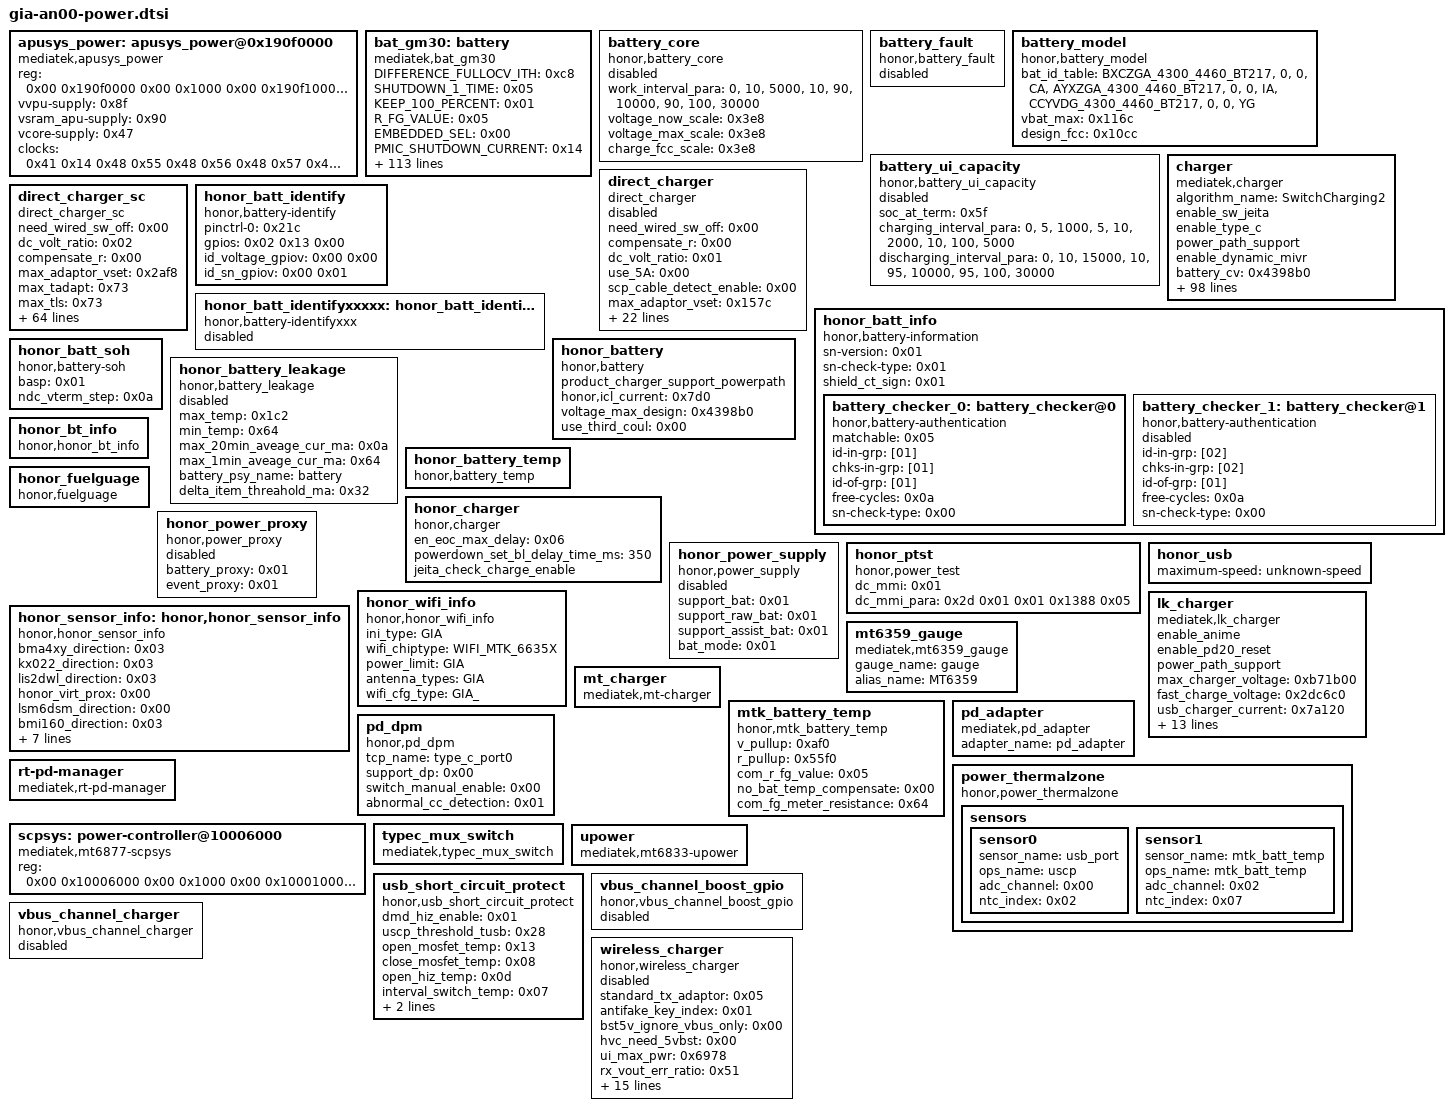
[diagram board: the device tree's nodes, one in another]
// SPDX-License-Identifier: GPL-2.0
/*
 * HONOR GIA-AN00 / MT6877V/ZA 设备树分片
 * 由实机反编译 device.dts 自动还原，节点内容保持原样
 */

/* 40 个顶层节点 */

	apusys_power: apusys_power@0x190f0000 {
			compatible = "mediatek,apusys_power";
			reg = <0x00 0x190f0000 0x00 0x1000 0x00 0x190f1000 0x00 0x1000 0x00 0x19029000 0x00 0x1000>;
			reg-names = "apusys_rpc", "apusys_pcu", "apusys_vcore";
			vvpu-supply = <0x8f>;
			vsram_apu-supply = <0x90>;
			vcore-supply = <0x47>;
			clocks = <0x41 0x14 0x48 0x55 0x48 0x56 0x48 0x57 0x48 0x58 0x48 0x59 0x48 0x03 0x48 0x16 0x48 0x1d 0x91 0x00 0x91 0x01 0x91 0x02 0x91 0x03>;
			clock-names = "mtcmos_scp_sys_vpu", "clk_top_dsp_sel", "clk_top_dsp1_sel", "clk_top_dsp2_sel", "clk_top_dsp5_sel", "clk_top_ipu_if_sel", "clk_top_mainpll_d4_d2", "clk_top_univpll_d4_d2", "clk_top_univpll_d6_d2", "clk_apupll_apupll", "clk_apupll_npupll", "clk_apupll_apupll1", "clk_apupll_apupll2";
			phandle = <0x19c>;
		};

	bat_gm30: battery {
			compatible = "mediatek,bat_gm30";
			DIFFERENCE_FULLOCV_ITH = <0xc8>;
			SHUTDOWN_1_TIME = <0x05>;
			KEEP_100_PERCENT = <0x01>;
			R_FG_VALUE = <0x05>;
			EMBEDDED_SEL = <0x00>;
			PMIC_SHUTDOWN_CURRENT = <0x14>;
			FG_METER_RESISTANCE = <0x64>;
			CAR_TUNE_VALUE = <0x1f4>;
			PMIC_MIN_VOL = <0x82dc>;
			POWERON_SYSTEM_IBOOT = <0x1f4>;
			SHUTDOWN_GAUGE0_VOLTAGE = <0x84d0>;
			TEMPERATURE_T0 = <0x32>;
			TEMPERATURE_T1 = <0x19>;
			TEMPERATURE_T2 = <0x0a>;
			TEMPERATURE_T3 = <0x00>;
			TEMPERATURE_T4 = <0xfffffff6>;
			g_FG_PSEUDO100_T0 = <0x61>;
			g_FG_PSEUDO100_T1 = <0x61>;
			g_FG_PSEUDO100_T2 = <0x61>;
			g_FG_PSEUDO100_T3 = <0x61>;
			g_FG_PSEUDO100_T4 = <0x61>;
			Q_MAX_SYS_VOLTAGE_BAT0 = <0xd16>;
			Q_MAX_SYS_VOLTAGE_BAT1 = <0xd16>;
			Q_MAX_SYS_VOLTAGE_BAT2 = <0xd16>;
			Q_MAX_SYS_VOLTAGE_BAT3 = <0xd16>;
			COM_FG_METER_RESISTANCE = <0x64>;
			COM_R_FG_VALUE = <0x00>;
			enable_tmp_intr_suspend = <0x00>;
			ACTIVE_TABLE = <0x00>;
			MULTI_TEMP_GAUGE0 = <0x01>;
			battery0_profile_t0_num = <0x64>;
			battery0_profile_t0_col = <0x04>;
			battery0_profile_t0 = <0x00 0xab72 0x15e 0x150 0x1a2 0xaaec 0x15e 0x150 0x344 0xaa7b 0x16f 0x160 0x4e7 0xaa09 0x16a 0x15c 0x689 0xa997 0x167 0x159 0x82b 0xa92a 0x177 0x168 0x9cd 0xa8bd 0x177 0x168 0xb6f 0xa848 0x177 0x168 0xd11 0xa7da 0x177 0x168 0xeb4 0xa768 0x184 0x174 0x1056 0xa6f3 0x190 0x180 0x11f8 0xa67c 0x18b 0x17b 0x139a 0xa5ff 0x178 0x169 0x139a 0xa5ff 0x178 0x169 0x153c 0xa593 0x18d 0x17d 0x16df 0xa518 0x190 0x180 0x1881 0xa4a0 0x190 0x180 0x1a23 0xa42b 0x190 0x180 0x1bc5 0xa3b5 0x190 0x180 0x1d67 0xa341 0x191 0x181 0x1f09 0xa2d4 0x1a6 0x195 0x20ac 0xa260 0x197 0x187 0x224e 0xa1f1 0x19e 0x18d 0x23f0 0xa183 0x1a9 0x198 0x2592 0xa112 0x1a3 0x192 0x2734 0xa09f 0x192 0x182 0x28d7 0xa03b 0x1a7 0x196 0x2a79 0x9fce 0x1a9 0x198 0x2c1b 0x9f68 0x1a9 0x198 0x2dbd 0x9f03 0x1a9 0x198 0x2f5f 0x9e9f 0x1a9 0x198 0x3101 0x9e3c 0x1ac 0x19b 0x32a4 0x9de0 0x1c1 0x1af 0x3446 0x9d7c 0x1c2 0x1b0 0x35e8 0x9d1e 0x1c2 0x1b0 0x378a 0x9cc6 0x1cd 0x1bb 0x392c 0x9c70 0x1e2 0x1cf 0x3acf 0x9c14 0x1f7 0x1e3 0x3c71 0x9bb8 0x20c 0x1f7 0x3e13 0x9b54 0x221 0x20b 0x3fb5 0x9ac3 0x1f6 0x1e2 0x4157 0x9a24 0x1c3 0x1b1 0x42f9 0x9998 0x1a1 0x190 0x449c 0x992f 0x190 0x180 0x463e 0x98dc 0x190 0x180 0x47e0 0x9890 0x190 0x180 0x4982 0x984b 0x190 0x180 0x4b24 0x9809 0x190 0x180 0x4cc7 0x97c6 0x188 0x178 0x4e69 0x9784 0x177 0x168 0x500b 0x974a 0x177 0x168 0x51ad 0x9718 0x18c 0x17c 0x534f 0x96df 0x190 0x180 0x54f1 0x96a9 0x190 0x180 0x5694 0x9677 0x190 0x180 0x5836 0x9645 0x190 0x180 0x59d8 0x9613 0x190 0x180 0x5b7a 0x95e9 0x190 0x180 0x5d1c 0x95b8 0x190 0x180 0x5ebf 0x9591 0x19d 0x18c 0x6061 0x956c 0x1a9 0x198 0x6203 0x9542 0x1a9 0x198 0x63a5 0x9518 0x1a9 0x198 0x6547 0x94f7 0x1a9 0x198 0x66e9 0x94d6 0x1bb 0x1a9 0x688c 0x94b4 0x1c2 0x1b0 0x6a2e 0x948b 0x1c2 0x1b0 0x6bd0 0x9453 0x1bc 0x1aa 0x6d72 0x940e 0x1a7 0x196 0x6f14 0x93b2 0x192 0x182 0x70b7 0x936c 0x190 0x180 0x7259 0x9335 0x190 0x180 0x73fb 0x92fe 0x190 0x180 0x759d 0x92c7 0x190 0x180 0x773f 0x9294 0x190 0x180 0x78e1 0x9262 0x190 0x180 0x7a84 0x9230 0x190 0x180 0x7c26 0x9204 0x190 0x180 0x7dc8 0x91da 0x19b 0x18b 0x7f6a 0x91a8 0x1a9 0x198 0x810c 0x9164 0x1a6 0x195 0x82af 0x9119 0x191 0x181 0x8451 0x90dd 0x1a4 0x193 0x85f3 0x909c 0x1a9 0x198 0x8795 0x904c 0x19e 0x18d 0x8937 0x9004 0x189 0x179 0x8ad9 0x8fe7 0x17a 0x16b 0x8c7c 0x8fde 0x18f 0x17f 0x8e1e 0x8fd6 0x1a4 0x193 0x8fc0 0x8fc7 0x1b9 0x1a7 0x9162 0x8fad 0x1da 0x1c7 0x9304 0x8f66 0x1ec 0x1d8 0x94a7 0x8eb6 0x1db 0x1c8 0x9649 0x8d46 0x1db 0x1c8 0x97eb 0x8b5b 0x204 0x1ef 0x998d 0x88ea 0x24f 0x237 0x9b2f 0x858f 0x2bb 0x29f 0x9cd1 0x802c 0x518 0x4e4 0x9e74 0x76cd 0xc4e 0xbd0 0xa016 0x6f40 0x52d 0x4f8 0xa1b8 0x6f40 0x52d 0x4f8>;
			battery0_profile_t1_num = <0x64>;
			battery0_profile_t1_col = <0x04>;
			battery0_profile_t1 = <0x00 0xaba4 0x28a 0x270 0x1a2 0xab40 0x28a 0x270 0x344 0xaadb 0x29b 0x280 0x4e7 0xaa77 0x2a3 0x288 0x689 0xaa13 0x2a3 0x288 0x82b 0xa9ac 0x2a3 0x288 0x9cd 0xa940 0x2a3 0x288 0xb6f 0xa8d3 0x28e 0x274 0xd11 0xa866 0x29b 0x280 0xeb4 0xa7f4 0x296 0x27c 0x1056 0xa783 0x293 0x279 0x11f8 0xa714 0x2a3 0x288 0x139a 0xa69f 0x2a3 0x288 0x153c 0xa62a 0x2a3 0x288 0x16df 0xa5ae 0x291 0x277 0x1881 0xa536 0x28a 0x270 0x1a23 0xa4c1 0x294 0x27a 0x1bc5 0xa44b 0x29e 0x283 0x1d67 0xa3d7 0x28b 0x271 0x1f09 0xa368 0x2a1 0x286 0x20ac 0xa2f3 0x2a3 0x288 0x224e 0xa27e 0x2a3 0x288 0x23f0 0xa20d 0x2a3 0x288 0x2592 0xa1a1 0x2a9 0x28e 0x2734 0xa134 0x2bc 0x2a0 0x28d7 0xa0c7 0x2bc 0x2a0 0x2a79 0xa05a 0x2bc 0x2a0 0x2c1b 0x9fee 0x2bc 0x2a0 0x2dbd 0x9f85 0x2c7 0x2ab 0x2f5f 0x9f21 0x2d5 0x2b8 0x3101 0x9ebd 0x2d8 0x2bb 0x32a4 0x9e58 0x2ed 0x2cf 0x3446 0x9dfc 0x302 0x2e3 0x35e8 0x9d9a 0x307 0x2e8 0x378a 0x9d3a 0x312 0x2f3 0x392c 0x9cde 0x32f 0x30e 0x3acf 0x9c82 0x355 0x333 0x3c71 0x9c26 0x36a 0x347 0x3e13 0x9bca 0x393 0x36e 0x3fb5 0x9b54 0x38d 0x369 0x4157 0x9abf 0x349 0x327 0x42f9 0x9a21 0x2e8 0x2ca 0x449c 0x9999 0x29f 0x284 0x463e 0x992c 0x28a 0x270 0x47e0 0x98d8 0x275 0x25c 0x4982 0x988b 0x271 0x258 0x4b24 0x9840 0x265 0x24c 0x4cc7 0x97fb 0x260 0x248 0x4e69 0x97c0 0x275 0x25c 0x500b 0x9786 0x28a 0x270 0x51ad 0x974b 0x28a 0x270 0x534f 0x9711 0x279 0x260 0x54f1 0x96db 0x27e 0x264 0x5694 0x96a6 0x281 0x267 0x5836 0x966f 0x276 0x25d 0x59d8 0x9645 0x28a 0x270 0x5b7a 0x9613 0x28a 0x270 0x5d1c 0x95e7 0x28a 0x270 0x5ebf 0x95be 0x28a 0x270 0x6061 0x9594 0x28a 0x270 0x6203 0x956a 0x28a 0x270 0x63a5 0x9540 0x28b 0x271 0x6547 0x951e 0x2a0 0x285 0x66e9 0x94fd 0x2a3 0x288 0x688c 0x94db 0x2b1 0x295 0x6a2e 0x94ba 0x2bc 0x2a0 0x6bd0 0x9496 0x2bc 0x2a0 0x6d72 0x946c 0x2bc 0x2a0 0x6f14 0x9442 0x2bc 0x2a0 0x70b7 0x9411 0x2a9 0x28e 0x7259 0x93df 0x294 0x27a 0x73fb 0x93ad 0x28a 0x270 0x759d 0x937b 0x284 0x26a 0x773f 0x9347 0x271 0x258 0x78e1 0x930d 0x271 0x258 0x7a84 0x92e2 0x284 0x26a 0x7c26 0x92b2 0x27b 0x262 0x7dc8 0x9288 0x271 0x258 0x7f6a 0x9261 0x271 0x258 0x810c 0x922d 0x271 0x258 0x82af 0x91ea 0x271 0x258 0x8451 0x91a7 0x271 0x258 0x85f3 0x916a 0x271 0x258 0x8795 0x912b 0x271 0x258 0x8937 0x90e3 0x271 0x258 0x8ad9 0x9095 0x271 0x258 0x8c7c 0x906c 0x271 0x258 0x8e1e 0x9062 0x285 0x26b 0x8fc0 0x9053 0x27a 0x261 0x9162 0x9047 0x289 0x26f 0x9304 0x9035 0x2a3 0x288 0x94a7 0x900b 0x2aa 0x28f 0x9649 0x8fb7 0x2d4 0x2b7 0x97eb 0x8e75 0x2c0 0x2a4 0x998d 0x8cb2 0x2dd 0x2c0 0x9b2f 0x8a60 0x313 0x2f4 0x9cd1 0x8746 0x37b 0x357 0x9e74 0x829b 0x508 0x4d4 0xa016 0x7aaa 0xa3c 0x9d3 0xa1b8 0x7166 0xa0f 0x9a8>;
			battery0_profile_t2_num = <0x64>;
			battery0_profile_t2_col = <0x04>;
			battery0_profile_t2 = <0x00 0xabcc 0x2bc 0x2a0 0x1a2 0xab81 0x2bc 0x2a0 0x344 0xab21 0x43f 0x414 0x4e7 0xaabd 0x4fb 0x4c8 0x689 0xaa59 0x4fb 0x4c8 0x82b 0xa9f2 0x4f6 0x4c3 0x9cd 0xa986 0x4e2 0x4b0 0xb6f 0xa921 0x4f7 0x4c4 0xd11 0xa8af 0x4ea 0x4b8 0xeb4 0xa83f 0x4e2 0x4b0 0x1056 0xa7cf 0x4e2 0x4b0 0x11f8 0xa75a 0x4e2 0x4b0 0x139a 0xa6e5 0x4e2 0x4b0 0x153c 0xa670 0x4e2 0x4b0 0x16df 0xa5fb 0x4e2 0x4b0 0x1881 0xa580 0x4d4 0x4a3 0x1a23 0xa50a 0x4d3 0x4a2 0x1bc5 0xa499 0x4dd 0x4ab 0x1d67 0xa41c 0x4c9 0x498 0x1f09 0xa3a5 0x4c9 0x498 0x20ac 0xa337 0x4dc 0x4aa 0x224e 0xa2c4 0x4d3 0x4a2 0x23f0 0xa24f 0x4c9 0x498 0x2592 0xa1dd 0x4cf 0x49e 0x2734 0xa170 0x4e2 0x4b0 0x28d7 0xa103 0x4e2 0x4b0 0x2a79 0xa096 0x4f5 0x4c2 0x2c1b 0xa02a 0x4fb 0x4c8 0x2dbd 0x9fc1 0x506 0x4d3 0x2f5f 0x9f5d 0x51b 0x4e7 0x3101 0x9ef9 0x530 0x4fb 0x32a4 0x9e94 0x545 0x50f 0x3446 0x9e30 0x55a 0x523 0x35e8 0x9dcc 0x56f 0x537 0x378a 0x9d67 0x583 0x54b 0x392c 0x9d06 0x5a0 0x566 0x3acf 0x9ca9 0x5c3 0x588 0x3c71 0x9c44 0x5c3 0x588 0x3e13 0x9bd8 0x5c3 0x588 0x3fb5 0x9b5e 0x5a3 0x569 0x4157 0x9ad7 0x556 0x51f 0x42f9 0x9a4c 0x4fd 0x4ca 0x449c 0x99c9 0x4be 0x48d 0x463e 0x9954 0x47f 0x451 0x47e0 0x98f8 0x47e 0x450 0x4982 0x98a1 0x46d 0x440 0x4b24 0x9852 0x465 0x438 0x4cc7 0x980a 0x465 0x438 0x4e69 0x97c7 0x465 0x438 0x500b 0x9784 0x465 0x438 0x51ad 0x974a 0x465 0x438 0x534f 0x970f 0x465 0x438 0x54f1 0x96d5 0x458 0x42c 0x5694 0x969e 0x455 0x429 0x5836 0x966c 0x465 0x438 0x59d8 0x963a 0x465 0x438 0x5b7a 0x9607 0x465 0x438 0x5d1c 0x95d5 0x465 0x438 0x5ebf 0x95a9 0x465 0x438 0x6061 0x957f 0x46f 0x442 0x6203 0x9555 0x47e 0x450 0x63a5 0x952c 0x47f 0x451 0x6547 0x950a 0x494 0x465 0x66e9 0x94e9 0x4a9 0x479 0x688c 0x94c2 0x4a2 0x473 0x6a2e 0x949c 0x4a1 0x472 0x6bd0 0x947a 0x4b0 0x480 0x6d72 0x9459 0x4b0 0x480 0x6f14 0x9437 0x4b0 0x480 0x70b7 0x941e 0x4c3 0x492 0x7259 0x93f9 0x4ba 0x48a 0x73fb 0x93d3 0x4b0 0x480 0x759d 0x93ad 0x4aa 0x47a 0x773f 0x937a 0x495 0x466 0x78e1 0x9348 0x480 0x452 0x7a84 0x9316 0x47e 0x450 0x7c26 0x92ea 0x47e 0x450 0x7dc8 0x92c0 0x489 0x45b 0x7f6a 0x9296 0x497 0x468 0x810c 0x926a 0x497 0x468 0x82af 0x922e 0x497 0x468 0x8451 0x91ec 0x4ab 0x47b 0x85f3 0x91af 0x4b0 0x480 0x8795 0x9170 0x4b0 0x480 0x8937 0x9127 0x4b0 0x480 0x8ad9 0x90d6 0x4b8 0x488 0x8c7c 0x9093 0x4e1 0x4af 0x8e1e 0x9079 0x4e2 0x4b0 0x8fc0 0x9067 0x503 0x4d0 0x9162 0x9051 0x514 0x4e0 0x9304 0x903b 0x52d 0x4f8 0x94a7 0x9024 0x567 0x530 0x9649 0x8ff1 0x591 0x558 0x97eb 0x8f41 0x5d0 0x594 0x998d 0x8dbf 0x60f 0x5d1 0x9b2f 0x8bb0 0x681 0x63e 0x9cd1 0x88f6 0x737 0x6ed 0x9e74 0x8518 0x892 0x83a 0xa016 0x7f24 0xbdf 0xb65 0xa1b8 0x7242 0xc80 0xc00>;
			battery0_profile_t3_num = <0x64>;
			battery0_profile_t3_col = <0x04>;
			battery0_profile_t3 = <0x00 0xab9a 0x7bc 0x76d 0x1a2 0xab36 0x7b8 0x769 0x344 0xaad1 0x8d5 0x87b 0x4e7 0xaa68 0x960 0x900 0x689 0xa9ff 0x960 0x900 0x82b 0xa998 0x960 0x900 0x9cd 0xa92c 0x960 0x900 0xb6f 0xa8bf 0x94b 0x8ec 0xd11 0xa852 0x947 0x8e8 0xeb4 0xa7df 0x93a 0x8dc 0x1056 0xa768 0x91b 0x8be 0x11f8 0xa6f3 0x8fc 0x8a0 0x139a 0xa67e 0x8fb 0x89f 0x153c 0xa609 0x8e6 0x88b 0x16df 0xa594 0x8d1 0x877 0x1881 0xa51f 0x8bc 0x863 0x1a23 0xa4aa 0x8b1 0x858 0x1bc5 0xa435 0x8ab 0x852 0x1d67 0xa3c0 0x896 0x83e 0x1f09 0xa34a 0x881 0x82a 0x20ac 0xa2d5 0x87f 0x828 0x224e 0xa266 0x87f 0x828 0x23f0 0xa1f5 0x875 0x81e 0x2592 0xa183 0x866 0x810 0x2734 0xa116 0x868 0x812 0x28d7 0xa0a9 0x87d 0x826 0x2a79 0xa03c 0x892 0x83a 0x2c1b 0x9fd6 0x898 0x840 0x2dbd 0x9f6d 0x898 0x840 0x2f5f 0x9f03 0x89f 0x847 0x3101 0x9e9f 0x8b7 0x85e 0x32a4 0x9e3a 0x8e0 0x885 0x3446 0x9dd6 0x8e3 0x888 0x35e8 0x9d72 0x8f3 0x897 0x378a 0x9d09 0x8fc 0x8a0 0x392c 0x9c9f 0x8fc 0x8a0 0x3acf 0x9c38 0x8f9 0x89d 0x3c71 0x9bc3 0x8e4 0x889 0x3e13 0x9b46 0x8bb 0x862 0x3fb5 0x9ac2 0x871 0x81b 0x4157 0x9a3c 0x81e 0x7cb 0x42f9 0x99c0 0x7d9 0x789 0x449c 0x9954 0x7b3 0x764 0x463e 0x98f0 0x79e 0x750 0x47e0 0x9894 0x78a 0x73d 0x4982 0x9845 0x785 0x738 0x4b24 0x97fa 0x779 0x72c 0x4cc7 0x97b2 0x76c 0x720 0x4e69 0x9770 0x770 0x724 0x500b 0x9736 0x785 0x738 0x51ad 0x96fb 0x79a 0x74c 0x534f 0x96c1 0x78d 0x740 0x54f1 0x9686 0x785 0x738 0x5694 0x964e 0x78e 0x741 0x5836 0x961c 0x7a3 0x755 0x59d8 0x95ea 0x7b8 0x769 0x5b7a 0x95c0 0x7cd 0x77d 0x5d1c 0x958f 0x7d0 0x780 0x5ebf 0x9563 0x7de 0x78d 0x6061 0x9539 0x7e9 0x798 0x6203 0x9511 0x7f4 0x7a3 0x63a5 0x94f0 0x81e 0x7cb 0x6547 0x94ce 0x848 0x7f3 0x66e9 0x94a5 0x83b 0x7e7 0x688c 0x9481 0x842 0x7ed 0x6a2e 0x9460 0x861 0x80b 0x6bd0 0x943e 0x87f 0x828 0x6d72 0x941e 0x881 0x82a 0x6f14 0x9405 0x896 0x83e 0x70b7 0x93ec 0x8bd 0x864 0x7259 0x93d2 0x8ca 0x870 0x73fb 0x93b5 0x8ca 0x870 0x759d 0x9391 0x8d0 0x876 0x773f 0x9367 0x8e3 0x888 0x78e1 0x933d 0x8e3 0x888 0x7a84 0x9314 0x8f6 0x89a 0x7c26 0x92e4 0x8fc 0x8a0 0x7dc8 0x92b6 0x912 0x8b5 0x7f6a 0x9289 0x943 0x8e4 0x810c 0x9255 0x97f 0x91e 0x82af 0x9211 0x9a9 0x946 0x8451 0x91ce 0x9d3 0x96e 0x85f3 0x918b 0xa0d 0x9a6 0x8795 0x9143 0xa4c 0x9e3 0x8937 0x90ee 0xa92 0xa26 0x8ad9 0x9094 0xae6 0xa76 0x8c7c 0x906b 0xb3a 0xac7 0x8e1e 0x9049 0xbb7 0xb3f 0x8fc0 0x902e 0xc45 0xbc7 0x9162 0x9015 0xcfc 0xc77 0x9304 0x8ff5 0xde6 0xd58 0x94a7 0x8fbe 0xf07 0xe6d 0x9649 0x8f50 0x106b 0xfc3 0x97eb 0x8e01 0x1222 0x1168 0x998d 0x8c09 0x1494 0x13c1 0x9b2f 0x895f 0x18a6 0x17aa 0x9cd1 0x8584 0x20a5 0x1f57 0x9e74 0x7fd2 0x29d9 0x282c 0xa016 0x7684 0x16f3 0x1608 0xa1b8 0x7684 0x16f3 0x1608>;
			battery0_profile_t4_num = <0x64>;
			battery0_profile_t4_col = <0x04>;
			battery0_profile_t4 = <0x00 0xabc2 0x128e 0x11d0 0x1a2 0xab34 0x128e 0x11d0 0x344 0xaab3 0x129f 0x11e0 0x4e7 0xaa40 0x12b4 0x11f4 0x689 0xa9d3 0x12a6 0x11e7 0x82b 0xa965 0x1275 0x11b8 0x9cd 0xa8f0 0x1274 0x11b7 0xb6f 0xa883 0x124a 0x118f 0xd11 0xa80f 0x1220 0x1166 0xeb4 0xa799 0x11f6 0x113e 0x1056 0xa722 0x11cc 0x1116 0x11f8 0xa6ad 0x11a2 0x10ed 0x139a 0xa638 0x117a 0x10c7 0x153c 0xa5c3 0x1165 0x10b3 0x16df 0xa54e 0x1150 0x109f 0x1881 0xa4d9 0x113b 0x108b 0x1a23 0xa464 0x1130 0x1080 0x1bc5 0xa3f1 0x1130 0x1080 0x1d67 0xa384 0x112e 0x107e 0x1f09 0xa30e 0x1119 0x106a 0x20ac 0xa299 0x1104 0x1056 0x224e 0xa22a 0x10fe 0x1050 0x23f0 0xa1b9 0x10f4 0x1046 0x2592 0xa147 0x10eb 0x103e 0x2734 0xa0da 0x10fc 0x104e 0x28d7 0xa06d 0x10e7 0x103a 0x2a79 0xa000 0x10f8 0x104a 0x2c1b 0x9f94 0x10fe 0x1050 0x2dbd 0x9f27 0x10fe 0x1050 0x2f5f 0x9eba 0x10fe 0x1050 0x3101 0x9e4f 0x1101 0x1053 0x32a4 0x9dea 0x1116 0x1067 0x3446 0x9d7e 0x1117 0x1068 0x35e8 0x9d0b 0x1108 0x105a 0x378a 0x9c96 0x10e7 0x103a 0x392c 0x9c21 0x10bd 0x1012 0x3acf 0x9bab 0x1090 0xfe6 0x3c71 0x9b2d 0x1052 0xfab 0x3e13 0x9ab0 0x1027 0xf82 0x3fb5 0x9a37 0xffc 0xf58 0x4157 0x99c6 0xfd2 0xf30 0x42f9 0x995c 0xfb1 0xf10 0x449c 0x98fa 0xf9c 0xefc 0x463e 0x989e 0xf87 0xee8 0x47e0 0x984a 0xf72 0xed4 0x4982 0x97fd 0xf7f 0xee0 0x4b24 0x97b2 0xf7a 0xedc 0x4cc7 0x976a 0xf6e 0xed0 0x4e69 0x9729 0xf73 0xed5 0x500b 0x96ee 0xf87 0xee8 0x51ad 0x96b4 0xf87 0xee8 0x534f 0x9679 0xf98 0xef8 0x54f1 0x9644 0xfad 0xf0c 0x5694 0x9612 0xfb9 0xf18 0x5836 0x95de 0xfb9 0xf18 0x59d8 0x95a4 0xfbb 0xf1a 0x5b7a 0x957a 0xfe5 0xf42 0x5d1c 0x9550 0xffd 0xf59 0x5ebf 0x9527 0x1012 0xf6d 0x6061 0x94fd 0x1027 0xf82 0x6203 0x94d5 0x1041 0xf9b 0x63a5 0x94b3 0x1069 0xfc1 0x6547 0x9489 0x107e 0xfd5 0x66e9 0x946e 0x10a6 0xffc 0x688c 0x944f 0x10c1 0x1015 0x6a2e 0x9432 0x10e0 0x1033 0x6bd0 0x9419 0x1104 0x1056 0x6d72 0x9400 0x111f 0x1070 0x6f14 0x93f0 0x1172 0x10bf 0x70b7 0x93d8 0x11b3 0x10fe 0x7259 0x93be 0x11e3 0x112c 0x73fb 0x93a5 0x1218 0x115f 0x759d 0x938a 0x1256 0x119a 0x773f 0x9367 0x1293 0x11d5 0x78e1 0x933d 0x12bd 0x11fd 0x7a84 0x931b 0x130d 0x124a 0x7c26 0x92ee 0x1360 0x129a 0x7dc8 0x92bc 0x13bf 0x12f5 0x7f6a 0x9287 0x1428 0x135a 0x810c 0x924a 0x1490 0x13bd 0x82af 0x91ff 0x14f9 0x1422 0x8451 0x91bb 0x1588 0x14ac 0x85f3 0x9177 0x163d 0x1559 0x8795 0x912a 0x16fb 0x1610 0x8937 0x90d3 0x17bf 0x16cc 0x8ad9 0x907d 0x1897 0x179b 0x8c7c 0x9043 0x1992 0x188c 0x8e1e 0x9021 0x1acb 0x19b9 0x8fc0 0x9000 0x1c47 0x1b25 0x9162 0x8fde 0x1e12 0x1cde 0x9304 0x8fb6 0x204a 0x1eff 0x94a7 0x8f78 0x231a 0x21b3 0x9649 0x8f0a 0x26b5 0x2529 0x97eb 0x8dc4 0x2bef 0x2a2d 0x998d 0x8bd4 0x35ff 0x33d6 0x9b2f 0x8967 0x4376 0x40c3 0x9cd1 0x85fa 0x3dd1 0x3b58 0x9e74 0x835e 0x3746 0x3510 0xa016 0x835e 0x3746 0x3510 0xa1b8 0x835e 0x3746 0x3510>;
			g_PMIC_MIN_VOL_row = <0x04>;
			g_PMIC_MIN_VOL_col = <0x0a>;
			g_PMIC_MIN_VOL = <0x82dc 0x82dc 0x82dc 0x82dc 0x80e8 0x80e8 0x80e8 0x80e8 0x82dc 0x82dc 0x82dc 0x82dc 0x7dc8 0x7dc8 0x7dc8 0x7dc8 0x7918 0x7918 0x7918 0x7918 0x7b0c 0x7b0c 0x7b0c 0x7b0c 0x7918 0x7918 0x7918 0x7918 0x7918 0x7918 0x7918 0x7918 0x7918 0x7918 0x7918 0x7918 0x7918 0x7918 0x7918 0x79e0>;
			g_PON_SYS_IBOOT_row = <0x04>;
			g_PON_SYS_IBOOT_col = <0x0a>;
			g_PON_SYS_IBOOT = <0x1388 0x1388 0x1388 0x1388 0x1388 0x1388 0x1388 0x1388 0x1388 0x1388 0x1388 0x1388 0x1388 0x1388 0x1388 0x1388 0x1388 0x1388 0x1388 0x1388 0x1388 0x1388 0x1388 0x1388 0x1388 0x1388 0x1388 0x1388 0x1388 0x1388 0x1388 0x1388 0x1388 0x1388 0x1388 0x1388 0x1388 0x1388 0x1388 0x1388>;
			g_QMAX_SYS_VOL_row = <0x04>;
			g_QMAX_SYS_VOL_col = <0x0a>;
			g_QMAX_SYS_VOL = <0x8886 0x8886 0x8886 0x8886 0x8886 0x8886 0x8886 0x8886 0x85ca 0x85ca 0x85ca 0x85ca 0x85ca 0x85ca 0x85ca 0x85ca 0x85ca 0x85ca 0x85ca 0x85ca 0x7ef4 0x7ef4 0x7ef4 0x7ef4 0x8020 0x8020 0x8020 0x8020 0x8020 0x8020 0x8020 0x8020 0x8020 0x8020 0x8020 0x8020 0x8020 0x8020 0x8020 0x8020>;
			g_FG_PSEUDO100_row = <0x04>;
			g_FG_PSEUDO100_col = <0x0a>;
			g_FG_PSEUDO100 = <0x64 0x64 0x64 0x64 0x64 0x64 0x64 0x64 0x64 0x64 0x64 0x64 0x64 0x64 0x64 0x64 0x64 0x64 0x64 0x64 0x64 0x64 0x64 0x64 0x64 0x64 0x64 0x64 0x64 0x64 0x64 0x64 0x64 0x64 0x64 0x64 0x64 0x64 0x64 0x64>;
			phandle = <0x141>;
			bat_para = "BXC_ZGA", "250000", "350000", "AYX_ZGA", "830000", "960000", "CCY_VDG", "0", "0";
			ntc_compensation_is = <0x01>;
			ntc_temp_compensation_para = "11000", "150", "10000", "130", "9000", "100", "8000", "80", "7000", "60", "6000", "50", "5000", "40", "3000", "30", "2000", "20";
			min_fcc = <0x2b4df0>;
			max_fcc = <0x419ce0>;
			dlpt_optimization;
			soc_algo_factor = <0x0f>;
			MULTI_BATTERY = <0x00>;
			SLEEP_CURRENT_AVG = <0x1f4>;
			low_capacity_volt_check_en = <0x00>;
			battery1_profile_t0_num = <0x64>;
			battery1_profile_t0_col = <0x04>;
			battery1_profile_t0 = <0x00 0xab90 0x15e 0x150 0x1a6 0xab11 0x15e 0x150 0x34b 0xaaa1 0x16f 0x160 0x4f1 0xaa33 0x177 0x168 0x697 0xa9c5 0x177 0x168 0x83d 0xa958 0x177 0x168 0x9e2 0xa8ea 0x177 0x168 0xb88 0xa87c 0x177 0x168 0xd2e 0xa807 0x177 0x168 0xed3 0xa797 0x186 0x176 0x1079 0xa725 0x190 0x180 0x121f 0xa6af 0x190 0x180 0x13c5 0xa639 0x190 0x180 0x156a 0xa5c3 0x190 0x180 0x1710 0xa54d 0x190 0x180 0x18b6 0xa4d0 0x190 0x180 0x1a5b 0xa45c 0x190 0x180 0x1c01 0xa3eb 0x190 0x180 0x1da7 0xa375 0x190 0x180 0x1f4d 0xa2fe 0x190 0x180 0x20f2 0xa288 0x190 0x180 0x2298 0xa219 0x190 0x180 0x243e 0xa1aa 0x19e 0x18d 0x25e3 0xa137 0x19f 0x18e 0x2789 0xa0c7 0x197 0x187 0x292f 0xa060 0x1a9 0x198 0x2ad5 0x9ff3 0x1a9 0x198 0x2c7a 0x9f8d 0x1a9 0x198 0x2e20 0x9f28 0x1b9 0x1a7 0x2fc6 0x9ec2 0x1c2 0x1b0 0x316c 0x9e5d 0x1c2 0x1b0 0x3311 0x9dfa 0x1c2 0x1b0 0x34b7 0x9d9d 0x1c2 0x1b0 0x365d 0x9d40 0x1d7 0x1c4 0x3802 0x9ce3 0x1db 0x1c8 0x39a8 0x9c87 0x1e9 0x1d5 0x3b4e 0x9c2a 0x1fe 0x1ea 0x3cf4 0x9bc8 0x213 0x1fe 0x3e99 0x9b55 0x21f 0x209 0x403f 0x9aa4 0x1cb 0x1b9 0x41e5 0x9a0a 0x19c 0x18c 0x438a 0x9996 0x190 0x180 0x4530 0x993a 0x185 0x175 0x46d6 0x98e8 0x177 0x168 0x487c 0x989e 0x17a 0x16b 0x4a21 0x985a 0x18f 0x17f 0x4bc7 0x9817 0x190 0x180 0x4d6d 0x97d3 0x17f 0x170 0x4f12 0x9795 0x184 0x174 0x50b8 0x975a 0x190 0x180 0x525e 0x9720 0x190 0x180 0x5404 0x96ee 0x190 0x180 0x55a9 0x96bb 0x190 0x180 0x574f 0x9681 0x190 0x180 0x58f5 0x9652 0x19e 0x18d 0x5a9a 0x9623 0x19f 0x18e 0x5c40 0x95f3 0x196 0x186 0x5de6 0x95c8 0x1a4 0x193 0x5f8c 0x9596 0x17a 0x16b 0x6131 0x9573 0x19e 0x18d 0x62d7 0x954b 0x1a9 0x198 0x647d 0x9521 0x19d 0x18c 0x6622 0x94f9 0x198 0x188 0x67c8 0x94d8 0x1ad 0x19c 0x696e 0x94b6 0x1c2 0x1b0 0x6b14 0x9494 0x1d8 0x1c5 0x6cb9 0x945d 0x1c9 0x1b7 0x6e5f 0x940b 0x1a6 0x195 0x7005 0x93b3 0x186 0x176 0x71aa 0x9368 0x17d 0x16e 0x7350 0x9335 0x190 0x180 0x74f6 0x9303 0x190 0x180 0x769c 0x92d0 0x190 0x180 0x7841 0x929d 0x19f 0x18e 0x79e7 0x926b 0x1a9 0x198 0x7b8d 0x923b 0x1a9 0x198 0x7d33 0x9210 0x1a5 0x194 0x7ed8 0x91dd 0x190 0x180 0x807e 0x91aa 0x190 0x180 0x8224 0x916a 0x190 0x180 0x83c9 0x9127 0x190 0x180 0x856f 0x90e7 0x199 0x189 0x8715 0x90a8 0x1a9 0x198 0x88bb 0x905c 0x1a8 0x197 0x8a60 0x9010 0x193 0x183 0x8c06 0x8ff7 0x190 0x180 0x8dac 0x8fe6 0x182 0x173 0x8f51 0x8fda 0x18c 0x17c 0x90f7 0x8fcf 0x1b0 0x19f 0x929d 0x8fbb 0x1c7 0x1b5 0x9443 0x8f91 0x1f1 0x1dd 0x95e8 0x8ee8 0x1cc 0x1ba 0x978e 0x8d9e 0x1c2 0x1b0 0x9934 0x8bdf 0x1e6 0x1d3 0x9ad9 0x89a7 0x21d 0x207 0x9c7f 0x86b5 0x254 0x23c 0x9e25 0x829b 0x2cb 0x2ae 0x9fcb 0x7a12 0x7fc 0x7aa 0xa170 0x6f36 0x4fb 0x4c8 0xa316 0x6f36 0x4fb 0x4c8>;
			battery1_profile_t1_num = <0x64>;
			battery1_profile_t1_col = <0x04>;
			battery1_profile_t1 = <0x1a6 0xab51 0x28a 0x270 0x34b 0xaaee 0x28a 0x270 0x4f1 0xaa88 0x28a 0x270 0x697 0xaa23 0x28a 0x270 0x83d 0xa9be 0x28a 0x270 0x9e2 0xa958 0x28c 0x272 0xb88 0xa8ea 0x2a1 0x286 0xd2e 0xa875 0x290 0x276 0xed3 0xa805 0x28a 0x270 0x1079 0xa793 0x28a 0x270 0x121f 0xa71d 0x28a 0x270 0x13c5 0xa6a7 0x28a 0x270 0x156a 0xa631 0x28a 0x270 0x1710 0xa5bb 0x28a 0x270 0x18b6 0xa545 0x28a 0x270 0x1a5b 0xa4cf 0x28a 0x270 0x1c01 0xa459 0x28a 0x270 0x1da7 0xa3e3 0x28a 0x270 0x1f4d 0xa36c 0x28a 0x270 0x20f2 0xa2f6 0x28a 0x270 0x2298 0xa287 0x29c 0x281 0x243e 0xa213 0x295 0x27b 0x25e3 0xa1a0 0x28a 0x270 0x2789 0xa132 0x291 0x277 0x292f 0xa0c5 0x2a6 0x28b 0x2ad5 0xa060 0x2bb 0x29f 0x2c7a 0x9ff3 0x2bc 0x2a0 0x2e20 0x9f8c 0x2cc 0x2af 0x2fc6 0x9f22 0x2c9 0x2ac 0x316c 0x9eba 0x2cc 0x2af 0x3311 0x9e5c 0x2ee 0x2d0 0x34b7 0x9df7 0x2ee 0x2d0 0x365d 0x9d9a 0x303 0x2e4 0x3802 0x9d3d 0x318 0x2f8 0x39a8 0x9cdb 0x32e 0x30d 0x3b4e 0x9c7a 0x343 0x322 0x3cf4 0x9c18 0x358 0x336 0x3e99 0x9ba9 0x367 0x344 0x403f 0x9b22 0x33d 0x31c 0x41e5 0x9a7d 0x2da 0x2bd 0x438a 0x99ec 0x28f 0x275 0x4530 0x9977 0x266 0x24d 0x46d6 0x9917 0x258 0x240 0x487c 0x98c6 0x25b 0x243 0x4a21 0x9882 0x270 0x257 0x4bc7 0x9836 0x25d 0x245 0x4d6d 0x97f1 0x258 0x240 0x4f12 0x97b3 0x258 0x240 0x50b8 0x9778 0x258 0x240 0x525e 0x973d 0x258 0x240 0x5404 0x9702 0x258 0x240 0x55a9 0x96cf 0x258 0x240 0x574f 0x969d 0x26a 0x251 0x58f5 0x966a 0x263 0x24b 0x5a9a 0x963c 0x262 0x24a 0x5c40 0x960f 0x26b 0x252 0x5de6 0x95dd 0x25a 0x242 0x5f8c 0x95b3 0x26f 0x256 0x6131 0x9589 0x271 0x258 0x62d7 0x9565 0x281 0x267 0x647d 0x953f 0x28a 0x270 0x6622 0x9517 0x28a 0x270 0x67c8 0x94f6 0x28a 0x270 0x696e 0x94d4 0x28a 0x270 0x6b14 0x94b2 0x2a0 0x285 0x6cb9 0x9490 0x2b5 0x299 0x6e5f 0x9468 0x2ae 0x293 0x7005 0x943a 0x299 0x27e 0x71aa 0x9405 0x27e 0x264 0x7350 0x93cc 0x258 0x240 0x74f6 0x93a2 0x258 0x240 0x769c 0x9370 0x258 0x240 0x7841 0x933d 0x267 0x24e 0x79e7 0x930b 0x266 0x24d 0x7b8d 0x92d8 0x251 0x239 0x7d33 0x92a8 0x243 0x22c 0x7ed8 0x9287 0x258 0x240 0x807e 0x925d 0x258 0x240 0x8224 0x9225 0x258 0x240 0x83c9 0x91ea 0x265 0x24c 0x856f 0x91ab 0x268 0x24f 0x8715 0x916c 0x25d 0x245 0x88bb 0x9138 0x271 0x258 0x8a60 0x90ec 0x271 0x258 0x8c06 0x9099 0x24c 0x234 0x8dac 0x9072 0x24d 0x235 0x8f51 0x9066 0x262 0x24a 0x90f7 0x905b 0x271 0x258 0x929d 0x904a 0x274 0x25b 0x9443 0x9039 0x289 0x26f 0x95e8 0x9018 0x29e 0x283 0x978e 0x8fa4 0x2a3 0x288 0x9934 0x8e8e 0x2af 0x294 0x9ad9 0x8cdc 0x2cc 0x2af 0x9c7f 0x8aac 0x2fa 0x2dc 0x9e25 0x87e4 0x33b 0x31a 0x9fcb 0x83ac 0x3f9 0x3d0 0xa170 0x7af7 0xb3e 0xacb 0xa316 0x6fd6 0x672 0x630>;
			battery1_profile_t2_num = <0x64>;
			battery1_profile_t2_col = <0x04>;
			battery1_profile_t2 = <0x00 0xabe0 0x2bc 0x2a0 0x1a6 0xab94 0x2bc 0x2a0 0x34b 0xab34 0x402 0x3d9 0x4f1 0xaace 0x497 0x468 0x697 0xaa69 0x497 0x468 0x83d 0xaa04 0x497 0x468 0x9e2 0xa99e 0x497 0x468 0xb88 0xa930 0x497 0x468 0xd2e 0xa8c3 0x497 0x468 0xed3 0xa855 0x497 0x468 0x1079 0xa7e3 0x48c 0x45d 0x121f 0xa76d 0x47e 0x450 0x13c5 0xa6f7 0x47e 0x450 0x156a 0xa681 0x47e 0x450 0x1710 0xa60b 0x47e 0x450 0x18b6 0xa595 0x47e 0x450 0x1a5b 0xa51f 0x47e 0x450 0x1c01 0xa4a9 0x47e 0x450 0x1da7 0xa433 0x47e 0x450 0x1f4d 0xa3bc 0x47e 0x450 0x20f2 0xa346 0x47e 0x450 0x2298 0xa2d0 0x46c 0x43f 0x243e 0xa25e 0x473 0x445 0x25e3 0xa1f0 0x488 0x45a 0x2789 0xa17f 0x497 0x468 0x292f 0xa10a 0x497 0x468 0x2ad5 0xa09d 0x497 0x468 0x2c7a 0xa037 0x4ab 0x47b 0x2e20 0x9fcb 0x4b0 0x480 0x2fc6 0x9f62 0x4c8 0x497 0x316c 0x9efa 0x4e2 0x4b0 0x3311 0x9e90 0x4e6 0x4b4 0x34b7 0x9e33 0x4fb 0x4c8 0x365d 0x9dce 0x510 0x4dc 0x3802 0x9d68 0x525 0x4f0 0x39a8 0x9d03 0x53b 0x505 0x3b4e 0x9c9e 0x550 0x51a 0x3cf4 0x9c34 0x55f 0x528 0x3e99 0x9bbc 0x558 0x521 0x403f 0x9b2d 0x504 0x4d1 0x41e5 0x9a96 0x49c 0x46d 0x438a 0x9a10 0x460 0x433 0x4530 0x999a 0x436 0x40b 0x46d6 0x9935 0x41a 0x3f0 0x487c 0x98e1 0x417 0x3ed 0x4a21 0x988d 0x402 0x3d9 0x4bc7 0x9849 0x401 0x3d8 0x4d6d 0x9805 0x401 0x3d8 0x4f12 0x97c2 0x401 0x3d8 0x50b8 0x9782 0x401 0x3d8 0x525e 0x9747 0x401 0x3d8 0x5404 0x970c 0x401 0x3d8 0x55a9 0x96d0 0x401 0x3d8 0x574f 0x969d 0x401 0x3d8 0x58f5 0x966a 0x40f 0x3e5 0x5a9a 0x9637 0x410 0x3e6 0x5c40 0x9605 0x401 0x3d8 0x5de6 0x95d3 0x406 0x3dd 0x5f8c 0x95a9 0x430 0x405 0x6131 0x957f 0x433 0x408 0x62d7 0x9555 0x433 0x408 0x647d 0x952b 0x433 0x408 0x6622 0x9503 0x43b 0x410 0x67c8 0x94e2 0x44c 0x420 0x696e 0x94c0 0x44c 0x420 0x6b14 0x949e 0x462 0x435 0x6cb9 0x947c 0x465 0x438 0x6e5f 0x945a 0x465 0x438 0x7005 0x9438 0x465 0x438 0x71aa 0x9417 0x465 0x438 0x7350 0x93f4 0x463 0x436 0x74f6 0x93ca 0x44e 0x422 0x769c 0x93a0 0x44c 0x420 0x7841 0x936f 0x43d 0x412 0x79e7 0x9338 0x428 0x3fd 0x7b8d 0x9300 0x413 0x3e9 0x7d33 0x92d0 0x405 0x3dc 0x7ed8 0x92af 0x41a 0x3f0 0x807e 0x9285 0x42f 0x404 0x8224 0x9254 0x433 0x408 0x83c9 0x9217 0x433 0x408 0x856f 0x91d7 0x43c 0x411 0x8715 0x919c 0x44c 0x420 0x88bb 0x9160 0x44c 0x420 0x8a60 0x9114 0x44c 0x420 0x8c06 0x90c1 0x45e 0x431 0x8dac 0x908f 0x465 0x438 0x8f51 0x9071 0x46f 0x442 0x90f7 0x905d 0x48b 0x45c 0x929d 0x9053 0x4b3 0x483 0x9443 0x903a 0x4c8 0x497 0x95e8 0x9018 0x4dd 0x4ab 0x978e 0x8fd0 0x512 0x4de 0x9934 0x8efb 0x545 0x50f 0x9ad9 0x8d7f 0x587 0x54e 0x9c7f 0x8b73 0x5fd 0x5c0 0x9e25 0x88d5 0x6a8 0x664 0x9fcb 0x84fa 0x7f9 0x7a7 0xa170 0x7db8 0xdd9 0xd4b 0xa316 0x713e 0x9c4 0x960>;
			battery1_profile_t3_num = <0x64>;
			battery1_profile_t3_col = <0x04>;
			battery1_profile_t3 = <0x00 0xabb8 0x708 0x6c0 0x1a6 0xab5b 0x708 0x6c0 0x34b 0xaaf8 0x7f8 0x7a6 0x4f1 0xaa92 0x873 0x81c 0x697 0xaa2d 0x87f 0x828 0x83d 0xa9c6 0x87a 0x823 0x9e2 0xa959 0x866 0x810 0xb88 0xa8f4 0x866 0x810 0xd2e 0xa87f 0x853 0x7fe 0xed3 0xa80f 0x83e 0x7ea 0x1079 0xa79d 0x834 0x7e0 0x121f 0xa727 0x82d 0x7d9 0x13c5 0xa6b1 0x818 0x7c5 0x156a 0xa63b 0x803 0x7b1 0x1710 0xa5c5 0x802 0x7b0 0x18b6 0xa54f 0x7f2 0x7a1 0x1a5b 0xa4d9 0x7d0 0x780 0x1c01 0xa463 0x7b7 0x768 0x1da7 0xa3ed 0x7b7 0x768 0x1f4d 0xa376 0x7b6 0x767 0x20f2 0xa300 0x7a1 0x753 0x2298 0xa291 0x7b0 0x761 0x243e 0xa21d 0x7a9 0x75b 0x25e3 0xa1aa 0x79e 0x750 0x2789 0xa13c 0x79e 0x750 0x292f 0xa0ce 0x7a1 0x753 0x2ad5 0xa061 0x7b6 0x767 0x2c7a 0x9ff3 0x7b7 0x768 0x2e20 0x9f85 0x7a7 0x759 0x2fc6 0x9f1c 0x7b6 0x767 0x316c 0x9eb7 0x7d8 0x788 0x3311 0x9e52 0x7ed 0x79c 0x34b7 0x9ded 0x802 0x7b0 0x365d 0x9d88 0x817 0x7c4 0x3802 0x9d1b 0x81b 0x7c8 0x39a8 0x9cb3 0x829 0x7d5 0x3b4e 0x9c42 0x821 0x7ce 0x3cf4 0x9bc2 0x7f1 0x7a0 0x3e99 0x9b3a 0x7b0 0x761 0x403f 0x9aab 0x75c 0x711 0x41e5 0x9a2a 0x71a 0x6d1 0x438a 0x99b2 0x6db 0x695 0x4530 0x9949 0x6bd 0x678 0x46d6 0x98ec 0x6b6 0x671 0x487c 0x9894 0x6a4 0x660 0x4a21 0x9850 0x6a4 0x660 0x4bc7 0x9804 0x6a4 0x660 0x4d6d 0x97bf 0x6a4 0x660 0x4f12 0x977c 0x6a4 0x660 0x50b8 0x973c 0x6a4 0x660 0x525e 0x9701 0x6a4 0x660 0x5404 0x96c6 0x6a5 0x661 0x55a9 0x9693 0x6ba 0x675 0x574f 0x9659 0x6bd 0x678 0x58f5 0x9624 0x6bd 0x678 0x5a9a 0x95f6 0x6d1 0x68b 0x5c40 0x95c9 0x6ef 0x6a8 0x5de6 0x9597 0x6f1 0x6aa 0x5f8c 0x956d 0x706 0x6be 0x6131 0x9543 0x708 0x6c0 0x62d7 0x9519 0x718 0x6cf 0x647d 0x94f3 0x72d 0x6e4 0x6622 0x94ce 0x73a 0x6f0 0x67c8 0x94a6 0x73e 0x6f4 0x696e 0x9484 0x753 0x708 0x6b14 0x9462 0x77e 0x731 0x6cb9 0x9447 0x797 0x749 0x6e5f 0x9428 0x79e 0x750 0x7005 0x940a 0x7b2 0x763 0x71aa 0x93ef 0x7ca 0x77a 0x7350 0x93cd 0x7b7 0x768 0x74f6 0x93ab 0x7b7 0x768 0x769c 0x9389 0x7ca 0x77a 0x7841 0x9361 0x7d0 0x780 0x79e7 0x9333 0x7d0 0x780 0x7b8d 0x9303 0x7d7 0x787 0x7d33 0x92d9 0x7ed 0x79c 0x7ed8 0x92af 0x802 0x7b0 0x807e 0x9285 0x82b 0x7d7 0x8224 0x9246 0x856 0x801 0x83c9 0x9203 0x880 0x829 0x856f 0x91c3 0x8b3 0x85a 0x8715 0x9186 0x8ed 0x892 0x88bb 0x9141 0x918 0x8bb 0x8a60 0x90e4 0x958 0x8f8 0x8c06 0x9096 0x9a9 0x946 0x8dac 0x9067 0xa0c 0x9a5 0x8f51 0x9049 0xa8a 0xa1e 0x90f7 0x9030 0xb2b 0xab9 0x929d 0x9016 0xbeb 0xb71 0x9443 0x8ff4 0xcbe 0xc3c 0x95e8 0x8fbb 0xdf4 0xd65 0x978e 0x8f33 0xf80 0xee1 0x9934 0x8e03 0x117a 0x10c7 0x9ad9 0x8c25 0x145c 0x138c 0x9c7f 0x89af 0x1935 0x1833 0x9e25 0x8670 0x21d7 0x207c 0x9fcb 0x8156 0x320e 0x300d 0xa170 0x79b8 0x1f0e 0x1dd0 0xa316 0x79b8 0x1f0e 0x1dd0>;
			battery1_profile_t4_num = <0x64>;
			battery1_profile_t4_col = <0x04>;
			battery1_profile_t4 = <0x00 0xabd6 0x109a 0xff0 0x1a6 0xab57 0x109a 0xff0 0x34b 0xaae0 0x10bc 0x1011 0x4f1 0xaa6f 0x10bf 0x1014 0x697 0xaa01 0x10aa 0xfff 0x83d 0xa994 0x108f 0xfe5 0x9e2 0xa926 0x1065 0xfbd 0xb88 0xa8b8 0x103b 0xf95 0xd2e 0xa843 0xffe 0xf5a 0xed3 0xa7d3 0xfcd 0xf2b 0x1079 0xa761 0xf98 0xef8 0x121f 0xa6eb 0xf60 0xec3 0x13c5 0xa675 0xf39 0xe9d 0x156a 0xa5ff 0xf24 0xe89 0x1710 0xa589 0xf0f 0xe75 0x18b6 0xa513 0xefa 0xe61 0x1a5b 0xa49d 0xef1 0xe58 0x1c01 0xa427 0xee9 0xe50 0x1da7 0xa3b2 0xedd 0xe45 0x1f4d 0xa344 0xef0 0xe57 0x20f2 0xa2ce 0xedb 0xe43 0x2298 0xa258 0xed8 0xe40 0x243e 0xa1e6 0xed8 0xe40 0x25e3 0xa173 0xed8 0xe40 0x2789 0xa100 0xedf 0xe47 0x292f 0xa092 0xef1 0xe58 0x2ad5 0xa025 0xef1 0xe58 0x2c7a 0x9fb7 0xef1 0xe58 0x2e20 0x9f49 0xf01 0xe67 0x2fc6 0x9ee0 0xf16 0xe7c 0x316c 0x9e78 0xf23 0xe88 0x3311 0x9e0a 0xf23 0xe88 0x34b7 0x9d9d 0xf23 0xe88 0x365d 0x9d27 0xf0e 0xe74 0x3802 0x9cb0 0xef9 0xe60 0x39a8 0x9c35 0xed6 0xe3e 0x3b4e 0x9bb6 0xeac 0xe16 0x3cf4 0x9b36 0xe7c 0xde8 0x3e99 0x9aaf 0xe3d 0xdab 0x403f 0x9a31 0xdfd 0xd6e 0x41e5 0x99c2 0xdd1 0xd44 0x438a 0x9960 0xdc5 0xd38 0x4530 0x98ff 0xdaf 0xd23 0x46d6 0x989f 0xd8c 0xd01 0x487c 0x984c 0xd7d 0xcf3 0x4a21 0x9800 0xd92 0xd07 0x4bc7 0x97bd 0xd93 0xd08 0x4d6d 0x9779 0xd93 0xd08 0x4f12 0x9736 0xd93 0xd08 0x50b8 0x96f6 0xd93 0xd08 0x525e 0x96bb 0xd98 0xd0d 0x5404 0x9680 0xdad 0xd21 0x55a9 0x964d 0xdc2 0xd35 0x574f 0x961b 0xdd7 0xd49 0x58f5 0x95e8 0xdde 0xd50 0x5a9a 0x95b5 0xde8 0xd5a 0x5c40 0x9585 0xdfd 0xd6e 0x5de6 0x955a 0xe10 0xd80 0x5f8c 0x9528 0xe10 0xd80 0x6131 0x9505 0xe37 0xda5 0x62d7 0x94dd 0xe52 0xdbf 0x647d 0x94b7 0xe67 0xdd4 0x6622 0x9495 0xe7c 0xde8 0x67c8 0x9474 0xe91 0xdfc 0x696e 0x9452 0xea6 0xe10 0x6b14 0x9438 0xed1 0xe39 0x6cb9 0x941f 0xeea 0xe51 0x6e5f 0x9405 0xf0d 0xe73 0x7005 0x93ec 0xf37 0xe9b 0x71aa 0x93d3 0xf5b 0xebe 0x7350 0x93ba 0xf74 0xed6 0x74f6 0x93a0 0xfb3 0xf12 0x769c 0x9387 0xff3 0xf50 0x7841 0x9361 0x1013 0xf6e 0x79e7 0x933c 0x103f 0xf99 0x7b8d 0x9314 0x1086 0xfdd 0x7d33 0x92e2 0x10da 0x102d 0x7ed8 0x92af 0x112e 0x107e 0x807e 0x927c 0x1197 0x10e3 0x8224 0x923c 0x1201 0x1149 0x83c9 0x91f9 0x1284 0x11c6 0x856f 0x91b5 0x1321 0x125d 0x8715 0x9170 0x13ce 0x1303 0x88bb 0x9123 0x148d 0x13bb 0x8a60 0x90c6 0x1560 0x1485 0x8c06 0x9078 0x1658 0x1573 0x8dac 0x9043 0x1771 0x1681 0x8f51 0x901d 0x18c2 0x17c4 0x90f7 0x8ffc 0x1a5f 0x1951 0x929d 0x8fd9 0x1c59 0x1b37 0x9443 0x8faf 0x1ee7 0x1dab 0x95e8 0x8f75 0x224e 0x20ef 0x978e 0x8eed 0x2731 0x25a0 0x9934 0x8dbd 0x2f37 0x2d54 0x9ad9 0x8bea 0x3df7 0x3b7c 0x9c7f 0x8997 0x46db 0x4405 0x9e25 0x8664 0x3fad 0x3d21 0x9fcb 0x8642 0x3f61 0x3cd8 0xa170 0x8642 0x3f61 0x3cd8 0xa316 0x8642 0x3f61 0x3cd8>;
			battery2_profile_t0_num = <0x64>;
			battery2_profile_t0_col = <0x04>;
			battery2_profile_t0 = <0x00 0xab2c 0x14a 0x13d 0x1a8 0xaabe 0x146 0x139 0x34f 0xaa57 0x156 0x148 0x4f7 0xa9eb 0x15e 0x150 0x69f 0xa97d 0x15e 0x150 0x847 0xa90f 0x15e 0x150 0x9ee 0xa8a1 0x15e 0x150 0xb96 0xa833 0x15e 0x150 0xd3e 0xa7bd 0x15e 0x150 0xee6 0xa74c 0x16e 0x15f 0x108d 0xa6da 0x16b 0x15c 0x1235 0xa663 0x166 0x158 0x13dd 0xa5ec 0x177 0x168 0x1585 0xa575 0x177 0x168 0x172c 0xa4f6 0x161 0x153 0x18d4 0xa485 0x170 0x161 0x1a7c 0xa412 0x169 0x15b 0x1c24 0xa39b 0x15e 0x150 0x1dcb 0xa327 0x164 0x156 0x1f73 0xa2b8 0x177 0x168 0x211b 0xa241 0x177 0x168 0x22c2 0xa1ca 0x163 0x155 0x246a 0xa159 0x15e 0x150 0x2612 0xa0ef 0x16b 0x15c 0x27ba 0xa085 0x177 0x168 0x2961 0xa019 0x17c 0x16d 0x2b09 0x9fb3 0x18f 0x17f 0x2cb1 0x9f45 0x179 0x16a 0x2e59 0x9ede 0x18a 0x17a 0x3000 0x9e78 0x190 0x180 0x31a8 0x9e17 0x19b 0x18b 0x3350 0x9dba 0x1a9 0x198 0x34f8 0x9d5d 0x1ac 0x19b 0x369f 0x9cff 0x1c2 0x1b0 0x3847 0x9ca2 0x1c2 0x1b0 0x39ef 0x9c4c 0x1d3 0x1c0 0x3b97 0x9bf2 0x1e8 0x1d4 0x3d3e 0x9b95 0x207 0x1f2 0x3ee6 0x9b2c 0x21b 0x205 0x408e 0x9aa2 0x1ed 0x1d9 0x4235 0x99f8 0x198 0x188 0x43dd 0x9975 0x16a 0x15c 0x4585 0x990e 0x15e 0x150 0x472d 0x98ba 0x16a 0x15c 0x48d4 0x986e 0x16f 0x160 0x4a7c 0x9823 0x15e 0x150 0x4c24 0x97e0 0x15e 0x150 0x4dcc 0x97a4 0x15e 0x150 0x4f73 0x9762 0x15e 0x150 0x511b 0x9729 0x16c 0x15d 0x52c3 0x96f2 0x16d 0x15e 0x546b 0x96ba 0x164 0x156 0x5612 0x9687 0x175 0x166 0x57ba 0x9654 0x160 0x152 0x5962 0x9621 0x15e 0x150 0x5b0a 0x95f4 0x16e 0x15f 0x5cb1 0x95c5 0x16b 0x15c 0x5e59 0x9596 0x166 0x158 0x6001 0x956b 0x177 0x168 0x61a9 0x9541 0x177 0x168 0x6350 0x951f 0x177 0x168 0x64f8 0x94f6 0x177 0x168 0x66a0 0x94d1 0x185 0x175 0x6847 0x94b0 0x190 0x180 0x69ef 0x948d 0x197 0x187 0x6b97 0x946a 0x1a9 0x198 0x6d3f 0x943f 0x1a9 0x198 0x6ee6 0x93f4 0x180 0x171 0x708e 0x93a1 0x166 0x158 0x7236 0x9357 0x16b 0x15c 0x73de 0x931a 0x177 0x168 0x7585 0x92e7 0x172 0x163 0x772d 0x92b5 0x15f 0x151 0x78d5 0x9282 0x175 0x166 0x7a7d 0x924f 0x177 0x168 0x7c24 0x9222 0x177 0x168 0x7dcc 0x91f8 0x177 0x168 0x7f74 0x91ca 0x177 0x168 0x811c 0x9197 0x177 0x168 0x82c3 0x9165 0x177 0x168 0x846b 0x9119 0x162 0x154 0x8613 0x90da 0x15e 0x150 0x87ba 0x909f 0x16b 0x15c 0x8962 0x9058 0x177 0x168 0x8b0a 0x900c 0x171 0x162 0x8cb2 0x8fdd 0x160 0x152 0x8e59 0x8fd5 0x175 0x166 0x9001 0x8fcc 0x177 0x168 0x91a9 0x8fbe 0x177 0x168 0x9351 0x8fad 0x19a 0x18a 0x94f8 0x8f86 0x1ca 0x1b8 0x96a0 0x8f10 0x1cf 0x1bc 0x9848 0x8de6 0x190 0x180 0x99f0 0x8c3e 0x1a5 0x194 0x9b97 0x8a26 0x1cc 0x1ba 0x9d3f 0x8773 0x212 0x1fd 0x9ee7 0x83a5 0x298 0x27d 0xa08f 0x7d66 0x6a5 0x661 0xa236 0x72ec 0xdde 0xd50 0xa3de 0x6fae 0x5c3 0x588>;
			battery2_profile_t1_num = <0x64>;
			battery2_profile_t1_col = <0x04>;
			battery2_profile_t1 = <0x00 0xab7c 0x28a 0x270 0x1a8 0xab0e 0x275 0x25c 0x34f 0xaaa7 0x282 0x268 0x4f7 0xaa41 0x28a 0x270 0x69f 0xa9db 0x294 0x27a 0x847 0xa973 0x29d 0x282 0x9ee 0xa905 0x28a 0x270 0xb96 0xa897 0x28a 0x270 0xd3e 0xa829 0x29d 0x282 0xee6 0xa7b4 0x293 0x279 0x108d 0xa73e 0x28a 0x270 0x1235 0xa6c6 0x28a 0x270 0x13dd 0xa64d 0x28a 0x270 0x1585 0xa5d7 0x28a 0x270 0x172c 0xa560 0x28a 0x270 0x18d4 0xa4ea 0x28a 0x270 0x1a7c 0xa473 0x28a 0x270 0x1c24 0xa3fc 0x28a 0x270 0x1dcb 0xa388 0x291 0x277 0x1f73 0xa319 0x2a0 0x285 0x211b 0xa2a2 0x28b 0x271 0x22c2 0xa234 0x29e 0x283 0x246a 0xa1bf 0x292 0x278 0x2612 0xa153 0x2a4 0x289 0x27ba 0xa0e9 0x2bc 0x2a0 0x2961 0xa07b 0x2bc 0x2a0 0x2b09 0xa00d 0x2bc 0x2a0 0x2cb1 0x9f9f 0x2bc 0x2a0 0x2e59 0x9f38 0x2bc 0x2a0 0x3000 0x9ed2 0x2cb 0x2ae 0x31a8 0x9e71 0x2e0 0x2c3 0x3350 0x9e11 0x2ee 0x2d0 0x34f8 0x9dad 0x2f5 0x2d7 0x369f 0x9d4f 0x31f 0x2ff 0x3847 0x9cf2 0x335 0x314 0x39ef 0x9c95 0x34a 0x328 0x3b97 0x9c38 0x35f 0x33c 0x3d3e 0x9bd7 0x36b 0x348 0x3ee6 0x9b6c 0x365 0x342 0x408e 0x9af0 0x349 0x327 0x4235 0x9a57 0x2f4 0x2d6 0x43dd 0x99be 0x29f 0x284 0x4585 0x9946 0x27a 0x261 0x472d 0x98e1 0x265 0x24c 0x48d4 0x988e 0x260 0x248 0x4a7c 0x9848 0x26d 0x254 0x4c24 0x97fc 0x258 0x240 0x4dcc 0x97b8 0x258 0x240 0x4f73 0x977c 0x258 0x240 0x511b 0x9740 0x258 0x240 0x52c3 0x9709 0x262 0x24a 0x546b 0x96d4 0x26a 0x251 0x5612 0x9699 0x258 0x240 0x57ba 0x9667 0x258 0x240 0x5962 0x9634 0x258 0x240 0x5b0a 0x9607 0x268 0x24f 0x5cb1 0x95dd 0x271 0x258 0x5e59 0x95b3 0x271 0x258 0x6001 0x9588 0x271 0x258 0x61a9 0x955d 0x273 0x25a 0x6350 0x9533 0x288 0x26e 0x64f8 0x9510 0x28a 0x270 0x66a0 0x94ee 0x299 0x27e 0x6847 0x94cc 0x2a3 0x288 0x69ef 0x94aa 0x2a3 0x288 0x6b97 0x9488 0x2a3 0x288 0x6d3f 0x9466 0x2a3 0x288 0x6ee6 0x943c 0x2a3 0x288 0x708e 0x9412 0x292 0x278 0x7236 0x93e2 0x27d 0x264 0x73de 0x93b3 0x271 0x258 0x7585 0x9386 0x271 0x258 0x772d 0x9353 0x26f 0x256 0x78d5 0x9320 0x25a 0x242 0x7a7d 0x92ee 0x258 0x240 0x7c24 0x92c1 0x258 0x240 0x7dcc 0x9297 0x258 0x240 0x7f74 0x926f 0x260 0x248 0x811c 0x924a 0x26d 0x254 0x82c3 0x9217 0x258 0x240 0x846b 0x91dc 0x26d 0x254 0x8613 0x919a 0x25f 0x247 0x87ba 0x9161 0x266 0x24d 0x8962 0x9126 0x271 0x258 0x8b0a 0x90dd 0x271 0x258 0x8cb2 0x908d 0x26f 0x256 0x8e59 0x9063 0x259 0x241 0x9001 0x9058 0x280 0x266 0x91a9 0x9050 0x28a 0x270 0x9351 0x9042 0x296 0x27c 0x94f8 0x902e 0x2ab 0x290 0x96a0 0x9008 0x2c1 0x2a5 0x9848 0x8fac 0x2d4 0x2b7 0x99f0 0x8e72 0x2bf 0x2a3 0x9b97 0x8cbe 0x2e0 0x2c3 0x9d3f 0x8a8e 0x319 0x2f9 0x9ee7 0x87aa 0x36d 0x34a 0xa08f 0x8380 0x448 0x41c 0xa236 0x7cca 0x832 0x7de 0xa3de 0x721a 0xbea 0xb70>;
			battery2_profile_t2_num = <0x64>;
			battery2_profile_t2_col = <0x04>;
			battery2_profile_t2 = <0x00 0xab54 0x690 0x64d 0x1a8 0xaaf7 0x68c 0x649 0x34f 0xaa8c 0x68b 0x648 0x4f7 0xaa23 0x68b 0x648 0x69f 0xa9b9 0x68b 0x648 0x847 0xa94e 0x691 0x64e 0x9ee 0xa8e7 0x6a4 0x660 0xb96 0xa879 0x6a4 0x660 0xd3e 0xa803 0x691 0x64e 0xee6 0xa78c 0x68b 0x648 0x108d 0xa716 0x67f 0x63c 0x1235 0xa69f 0x672 0x630 0x13dd 0xa628 0x672 0x630 0x1585 0xa5b2 0x672 0x630 0x172c 0xa53b 0x672 0x630 0x18d4 0xa4c4 0x672 0x630 0x1a7c 0xa44e 0x664 0x623 0x1c24 0xa3d7 0x659 0x618 0x1dcb 0xa360 0x659 0x618 0x1f73 0xa2eb 0x65c 0x61b 0x211b 0xa27d 0x671 0x62f 0x22c2 0xa20e 0x672 0x630 0x246a 0xa198 0x672 0x630 0x2612 0xa125 0x672 0x630 0x27ba 0xa0b7 0x67b 0x639 0x2961 0xa049 0x68b 0x648 0x2b09 0x9fdb 0x68c 0x649 0x2cb1 0x9f76 0x6a2 0x65e 0x2e59 0x9f10 0x6b7 0x672 0x3000 0x9eaa 0x6cc 0x686 0x31a8 0x9e45 0x6e1 0x69b 0x3350 0x9ddf 0x6ef 0x6a8 0x34f8 0x9d79 0x6ef 0x6a8 0x369f 0x9d14 0x6ef 0x6a8 0x3847 0x9cb6 0x719 0x6d0 0x39ef 0x9c52 0x721 0x6d8 0x3b97 0x9bed 0x72e 0x6e4 0x3d3e 0x9b7f 0x727 0x6de 0x3ee6 0x9b04 0x6f2 0x6ab 0x408e 0x9a7d 0x69b 0x657 0x4235 0x99f5 0x631 0x5f2 0x43dd 0x997d 0x601 0x5c4 0x4585 0x9912 0x5e6 0x5aa 0x472d 0x98b1 0x5d0 0x594 0x48d4 0x985a 0x5c3 0x588 0x4a7c 0x980e 0x5bf 0x584 0x4c24 0x97c2 0x5aa 0x570 0x4dcc 0x9786 0x5bf 0x584 0x4f73 0x9744 0x5b2 0x578 0x511b 0x9706 0x5b8 0x57d 0x52c3 0x96ce 0x5cd 0x592 0x546b 0x9699 0x5d6 0x59a 0x5612 0x965f 0x5c3 0x588 0x57ba 0x962c 0x5c3 0x588 0x5962 0x95f9 0x5c3 0x588 0x5b0a 0x95cc 0x5d3 0x597 0x5cb1 0x95a2 0x5f4 0x5b7 0x5e59 0x9574 0x606 0x5c8 0x6001 0x9545 0x5f9 0x5bc 0x61a9 0x9523 0x60e 0x5d0 0x6350 0x94f9 0x60e 0x5d0 0x64f8 0x94d5 0x632 0x5f3 0x66a0 0x94b3 0x640 0x600 0x6847 0x9492 0x64a 0x60a 0x69ef 0x946f 0x659 0x618 0x6b97 0x944d 0x659 0x618 0x6d3f 0x942b 0x659 0x618 0x6ee6 0x9409 0x66e 0x62c 0x708e 0x93ee 0x672 0x630 0x7236 0x93cf 0x672 0x630 0x73de 0x93ad 0x669 0x627 0x7585 0x9389 0x65e 0x61d 0x772d 0x935f 0x672 0x630 0x78d5 0x9335 0x672 0x630 0x7a7d 0x930a 0x65f 0x61e 0x7c24 0x92e0 0x668 0x626 0x7dcc 0x92b6 0x67d 0x63b 0x7f74 0x928b 0x68b 0x648 0x811c 0x925f 0x696 0x653 0x82c3 0x922d 0x6d5 0x68f 0x846b 0x91f1 0x700 0x6b8 0x8613 0x91af 0x719 0x6d0 0x87ba 0x9171 0x73c 0x6f2 0x8962 0x912e 0x770 0x724 0x8b0a 0x90df 0x7a4 0x756 0x8cb2 0x908e 0x7bb 0x76c 0x8e59 0x9064 0x7e5 0x794 0x9001 0x9051 0x849 0x7f4 0x91a9 0x9039 0x894 0x83c 0x9351 0x9025 0x925 0x8c7 0x94f8 0x900a 0x9f9 0x993 0x96a0 0x8fce 0xad6 0xa67 0x9848 0x8f3c 0xbd8 0xb5f 0x99f0 0x8dd8 0xcac 0xc2a 0x9b97 0x8be4 0xe34 0xda3 0x9d3f 0x8959 0x10ce 0x1022 0x9ee7 0x85e2 0x1517 0x143f 0xa08f 0x80a2 0x1ca0 0x1b7b 0xa236 0x7688 0x173e 0x1650 0xa3de 0x73f0 0x1068 0xfc0>;
			battery2_profile_t3_num = <0x64>;
			battery2_profile_t3_col = <0x04>;
			battery2_profile_t3 = <0x00 0xab54 0x5dc 0x5a0 0x1a8 0xaaf7 0x5dc 0x5a0 0x34f 0xaa7e 0xc2c 0xbaf 0x4f7 0xaa04 0xf0c 0xe72 0x69f 0xa991 0xf23 0xe88 0x847 0xa921 0xf23 0xe88 0x9ee 0xa8aa 0xf18 0xe7d 0xb96 0xa833 0xeae 0xe18 0xd3e 0xa7bd 0xeb9 0xe22 0xee6 0xa746 0xe80 0xdec 0x108d 0xa6d0 0xe4f 0xdbc 0x1235 0xa658 0xe29 0xd98 0x13dd 0xa5df 0xdfc 0xd6d 0x1585 0xa569 0xe0f 0xd7f 0x172c 0xa4f2 0xdfa 0xd6b 0x18d4 0xa47c 0xde5 0xd57 0x1a7c 0xa40b 0xdd0 0xd43 0x1c24 0xa398 0xdc5 0xd38 0x1dcb 0xa322 0xdbe 0xd31 0x1f73 0xa2ac 0xdac 0xd20 0x211b 0xa23e 0xdac 0xd20 0x22c2 0xa1c8 0xdac 0xd20 0x246a 0xa158 0xd8b 0xd00 0x2612 0xa0e9 0xd87 0xcfc 0x27ba 0xa07b 0xd93 0xd08 0x2961 0xa00f 0xd98 0xd0d 0x2b09 0x9fa9 0xdac 0xd20 0x2cb1 0x9f3b 0xdac 0xd20 0x2e59 0x9ed4 0xdbf 0xd32 0x3000 0x9e67 0xdc5 0xd38 0x31a8 0x9dfc 0xdc5 0xd38 0x3350 0x9d93 0xdbd 0xd30 0x34f8 0x9d25 0xdac 0xd20 0x369f 0x9cb7 0xdac 0xd20 0x3847 0x9c52 0xdc1 0xd34 0x39ef 0x9be5 0xdb3 0xd27 0x3b97 0x9b77 0xdac 0xd20 0x3d3e 0x9b01 0xd67 0xcde 0x3ee6 0x9a84 0xcfd 0xc78 0x408e 0x9a0d 0xcfb 0xc76 0x4235 0x9997 0xce6 0xc62 0x43dd 0x9928 0xc95 0xc14 0x4585 0x98c0 0xc60 0xbe1 0x472d 0x9863 0xc5a 0xbdc 0x48d4 0x980d 0xc5e 0xbdf 0x4a7c 0x97bc 0xc53 0xbd5 0x4c24 0x9778 0xc68 0xbe9 0x4dcc 0x9735 0xc7d 0xbfd 0x4f73 0x96f8 0xc80 0xc00 0x511b 0x96bd 0xc8f 0xc0e 0x52c3 0x9682 0xc8e 0xc0d 0x546b 0x9646 0xc87 0xc07 0x5612 0x960e 0xc9f 0xc1e 0x57ba 0x95e3 0xcca 0xc47 0x5962 0x95b1 0xce0 0xc5c 0x5b0a 0x957e 0xcf5 0xc70 0x5cb1 0x9550 0xd0a 0xc84 0x5e59 0x9526 0xd1f 0xc99 0x6001 0x94fb 0xd3a 0xcb3 0x61a9 0x94d2 0xd63 0xcda 0x6350 0x94b0 0xd78 0xcee 0x64f8 0x948e 0xda0 0xd14 0x66a0 0x9465 0xdbb 0xd2e 0x6847 0x9444 0xddd 0xd4f 0x69ef 0x9427 0xe07 0xd77 0x6b97 0x9407 0xe2d 0xd9c 0x6d3f 0x93ee 0xe43 0xdb1 0x6ee6 0x93d4 0xe6d 0xdd9 0x708e 0x93bb 0xea9 0xe13 0x7236 0x93a1 0xedb 0xe43 0x73de 0x9388 0xf0f 0xe75 0x7585 0x936e 0xf55 0xeb8 0x772d 0x9354 0xfaa 0xf0a 0x78d5 0x9332 0xfff 0xf5b 0x7a7d 0x9308 0x1053 0xfac 0x7c24 0x92e4 0x10c8 0x101c 0x7dcc 0x92b9 0x1123 0x1074 0x7f74 0x9286 0x117b 0x10c8 0x811c 0x9251 0x1204 0x114c 0x82c3 0x9216 0x12ac 0x11ed 0x846b 0x91d2 0x1341 0x127c 0x8613 0x918e 0x13f9 0x132c 0x87ba 0x914a 0x14d5 0x1400 0x8962 0x90fe 0x15be 0x14df 0x8b0a 0x90a9 0x16a7 0x15bf 0x8cb2 0x9059 0x179e 0x16ac 0x8e59 0x9026 0x18f1 0x17f2 0x9001 0x9004 0x1aa9 0x1998 0x91a9 0x8fe8 0x1cb9 0x1b93 0x9351 0x8fc5 0x1f1f 0x1de0 0x94f8 0x8f90 0x223c 0x20dd 0x96a0 0x8f35 0x2667 0x24de 0x9848 0x8e82 0x2b9a 0x29dc 0x99f0 0x8d27 0x324e 0x304b 0x9b97 0x8b33 0x3b3e 0x38df 0x9d3f 0x88c3 0x4302 0x4054 0x9ee7 0x8553 0x3c12 0x39ab 0xa08f 0x80e8 0x31b5 0x2fb8 0xa236 0x80e8 0x31b5 0x2fb8 0xa3de 0x80e8 0x31b5 0x2fb8>;
			battery2_profile_t4_num = <0x64>;
			battery2_profile_t4_col = <0x04>;
			battery2_profile_t4 = <0x00 0xab72 0x320 0x300 0x1a8 0xab37 0x320 0x300 0x34f 0xaaa1 0x178d 0x169c 0x4f7 0xaa08 0x20e4 0x1f93 0x69f 0xa97c 0x2165 0x200f 0x847 0xa8f2 0x21ab 0x2052 0x9ee 0xa863 0x2196 0x203e 0xb96 0xa7e4 0x2181 0x202a 0xd3e 0xa75d 0x2158 0x2003 0xee6 0xa6da 0x212d 0x1fd9 0x108d 0xa655 0x2102 0x1fb0 0x1235 0xa5d4 0x20be 0x1f6f 0x13dd 0xa55c 0x205e 0x1f13 0x1585 0xa4dd 0x201c 0x1ed3 0x172c 0xa466 0x1fb2 0x1e6d 0x18d4 0xa3e8 0x1f48 0x1e08 0x1a7c 0xa36f 0x1eed 0x1db0 0x1c24 0xa2f8 0x1ea3 0x1d69 0x1dcb 0xa284 0x1e71 0x1d39 0x1f73 0xa215 0x1e59 0x1d22 0x211b 0xa19e 0x1e2f 0x1cfa 0x22c2 0xa128 0x1e19 0x1ce5 0x246a 0xa0b8 0x1e03 0x1cd0 0x2612 0xa049 0x1dee 0x1cbc 0x27ba 0x9fdf 0x1dd9 0x1ca7 0x2961 0x9f77 0x1dbf 0x1c8e 0x2b09 0x9f08 0x1d94 0x1c65 0x2cb1 0x9e92 0x1d6a 0x1c3d 0x2e59 0x9e23 0x1d65 0x1c38 0x3000 0x9dad 0x1d65 0x1c38 0x31a8 0x9d35 0x1d42 0x1c16 0x3350 0x9cc1 0x1d03 0x1bda 0x34f8 0x9c53 0x1ccf 0x1ba8 0x369f 0x9be5 0x1ccf 0x1ba8 0x3847 0x9b77 0x1c8f 0x1b6b 0x39ef 0x9b09 0x1c84 0x1b60 0x3b97 0x9a9b 0x1c5b 0x1b39 0x3d3e 0x9a30 0x1c2f 0x1b0e 0x3ee6 0x99c8 0x1c20 0x1b00 0x408e 0x995b 0x1c19 0x1af9 0x4235 0x98f5 0x1bda 0x1abd 0x43dd 0x9897 0x1bd5 0x1ab8 0x4585 0x9841 0x1bc5 0x1aa9 0x472d 0x97ec 0x1b8c 0x1a72 0x48d4 0x979a 0x1b50 0x1a38 0x4a7c 0x9750 0x1b3f 0x1a28 0x4c24 0x970a 0x1b41 0x1a2a 0x4dcc 0x96c7 0x1b6c 0x1a53 0x4f73 0x968a 0x1ba8 0x1a8d 0x511b 0x964f 0x1bd9 0x1abc 0x52c3 0x9614 0x1c0f 0x1af0 0x546b 0x95db 0x1c47 0x1b25 0x5612 0x95a8 0x1c78 0x1b54 0x57ba 0x9575 0x1ccd 0x1ba6 0x5962 0x9543 0x1cf8 0x1bcf 0x5b0a 0x9516 0x1d44 0x1c18 0x5cb1 0x94ec 0x1d8c 0x1c5d 0x5e59 0x94c5 0x1dd5 0x1ca4 0x6001 0x94a3 0x1e24 0x1cef 0x61a9 0x9481 0x1e65 0x1d2e 0x6350 0x945f 0x1ea5 0x1d6b 0x64f8 0x9445 0x1f1e 0x1ddf 0x66a0 0x942b 0x1f8e 0x1e4b 0x6847 0x9417 0x200f 0x1ec7 0x69ef 0x9402 0x209c 0x1f4e 0x6b97 0x93e9 0x211f 0x1fcc 0x6d3f 0x93d0 0x21b3 0x205a 0x6ee6 0x93b6 0x2232 0x20d4 0x708e 0x939d 0x22e6 0x2181 0x7236 0x9383 0x23b3 0x2245 0x73de 0x936a 0x247d 0x2307 0x7585 0x934e 0x254e 0x23d0 0x772d 0x932c 0x264d 0x24c5 0x78d5 0x9309 0x2750 0x25bd 0x7a7d 0x92df 0x2863 0x26c5 0x7c24 0x92b5 0x2998 0x27ee 0x7dcc 0x9286 0x2ae2 0x292b 0x7f74 0x9253 0x2c47 0x2a82 0x811c 0x921e 0x2dc9 0x2bf4 0x82c3 0x91e2 0x2f5f 0x2d7a 0x846b 0x91a7 0x311b 0x2f24 0x8613 0x9164 0x32eb 0x30e2 0x87ba 0x9121 0x34cc 0x32af 0x8962 0x90dd 0x36be 0x348d 0x8b0a 0x909c 0x38bb 0x3676 0x8cb2 0x9062 0x3ab9 0x3860 0x8e59 0x902e 0x3cc0 0x3a52 0x9001 0x9003 0x3ed1 0x3c4e 0x91a9 0x8fe0 0x4106 0x3e6c 0x9351 0x8fb9 0x4394 0x40e0 0x94f8 0x8f8a 0x46bb 0x43e7 0x96a0 0x8f42 0x4add 0x47de 0x9848 0x8eba 0x5002 0x4ccf 0x99f0 0x8dc7 0x5112 0x4dd4 0x9b97 0x8c1a 0x4d21 0x4a0b 0x9d3f 0x89d0 0x47bd 0x44de 0x9ee7 0x89d0 0x4731 0x4458 0xa08f 0x89d0 0x4731 0x4458 0xa236 0x89d0 0x4731 0x4458 0xa3de 0x89d0 0x4731 0x4458>;
		};

	battery_core: battery_core {
			compatible = "honor,battery_core";
			work_interval_para = "0", "10", "5000", "10", "90", "10000", "90", "100", "30000";
			voltage_now_scale = <0x3e8>;
			voltage_max_scale = <0x3e8>;
			charge_fcc_scale = <0x3e8>;
			status = "disabled";
			phandle = <0xc1>;
		};

	battery_fault: battery_fault {
			compatible = "honor,battery_fault";
			status = "disabled";
			phandle = <0xc2>;
		};

	battery_model: battery_model {
			compatible = "honor,battery_model";
			status = "ok";
			phandle = <0xc3>;
			bat_id_table = "BXCZGA_4300_4460_BT217", "0", "0", "CA", "AYXZGA_4300_4460_BT217", "0", "0", "IA", "CCYVDG_4300_4460_BT217", "0", "0", "YG";
			vbat_max = <0x116c>;
			design_fcc = <0x10cc>;
		};

	battery_ui_capacity: battery_ui_capacity {
			compatible = "honor,battery_ui_capacity";
			soc_at_term = <0x5f>;
			charging_interval_para = "0", "5", "1000", "5", "10", "2000", "10", "100", "5000";
			discharging_interval_para = "0", "10", "15000", "10", "95", "10000", "95", "100", "30000";
			status = "disabled";
			phandle = <0xc4>;
		};

	charger: charger {
			compatible = "mediatek,charger";
			algorithm_name = "SwitchCharging2";
			enable_sw_jeita;
			enable_type_c;
			power_path_support;
			enable_dynamic_mivr;
			battery_cv = <0x4398b0>;
			max_charger_voltage = <0xb71b00>;
			min_charger_voltage = <0x4630c0>;
			min_charger_voltage_1 = <0x432380>;
			min_charger_voltage_2 = <0x401640>;
			max_dmivr_charger_current = <0x155cc0>;
			usb_charger_current_suspend = <0x00>;
			usb_charger_current_unconfigured = <0x11170>;
			usb_charger_current_configured = <0x7a120>;
			usb_charger_current = <0x7a120>;
			ac_charger_current = <0x1e8480>;
			ac_charger_input_current = <0x231860>;
			non_std_ac_charger_current = <0x124f80>;
			charging_host_charger_current = <0x16e360>;
			apple_1_0a_charger_current = <0x9eb10>;
			apple_2_1a_charger_current = "", "\f5";
			ta_ac_charger_current = <0x2dc6c0>;
			jeita_temp_above_t4_cv = <0x3e8fa0>;
			jeita_temp_t3_to_t4_cv = <0x3e8fa0>;
			jeita_temp_t2_to_t3_cv = <0x4398b0>;
			jeita_temp_t1_to_t2_cv = <0x4398b0>;
			jeita_temp_t0_to_t1_cv = <0x4398b0>;
			jeita_temp_below_t0_cv = <0x3e8fa0>;
			jeita_temp_t3_to_t4_cur = <0x155cc0>;
			jeita_temp_t2_to_t3_cur = <0x2ab980>;
			jeita_temp_t1_to_t2_cur = <0x124f80>;
			jeita_temp_t0_to_t1_cur = <0x668a0>;
			temp_t4_thres = <0x32>;
			temp_t4_thres_minus_x_degree = <0x2f>;
			temp_t3_thres = <0x2d>;
			temp_t3_thres_minus_x_degree = <0x2a>;
			temp_t2_thres = <0x0a>;
			temp_t2_thres_plus_x_degree = <0x0d>;
			temp_t1_thres = <0x05>;
			temp_t1_thres_plus_x_degree = <0x07>;
			temp_t0_thres = <0x00>;
			temp_t0_thres_plus_x_degree = <0x00>;
			temp_neg_10_thres = <0x00>;
			enable_min_charge_temp;
			min_charge_temp = <0x00>;
			min_charge_temp_plus_x_degree = <0x06>;
			max_charge_temp = <0x32>;
			max_charge_temp_minus_x_degree = <0x2f>;
			ta_12v_support;
			ta_9v_support;
			pe_ichg_level_threshold = <0xf4240>;
			ta_ac_12v_input_current = <0x30d400>;
			ta_ac_9v_input_current = <0x30d400>;
			ta_ac_7v_input_current = <0x30d400>;
			pe20_ichg_level_threshold = <0xf4240>;
			ta_start_battery_soc = <0x00>;
			ta_stop_battery_soc = <0x55>;
			high_temp_to_leave_pe40 = <0x2e>;
			high_temp_to_enter_pe40 = <0x27>;
			low_temp_to_leave_pe40 = <0x0a>;
			low_temp_to_enter_pe40 = <0x10>;
			pe40_single_charger_input_current = <0x2dc6c0>;
			pe40_single_charger_current = <0x2dc6c0>;
			pe40_dual_charger_input_current = <0x2dc6c0>;
			pe40_dual_charger_chg1_current = <0x1e8480>;
			pe40_dual_charger_chg2_current = <0x1e8480>;
			pe40_stop_battery_soc = <0x50>;
			pe40_r_cable_1a_lower = <0x22f>;
			pe40_r_cable_2a_lower = <0x1a4>;
			pe40_r_cable_3a_lower = <0x117>;
			chg1_ta_ac_charger_current = <0x16e360>;
			chg2_ta_ac_charger_current = <0x16e360>;
			slave_mivr_diff = <0x186a0>;
			dual_polling_ieoc = <0xb71b0>;
			cable_imp_threshold = <0x2bb>;
			vbat_cable_imp_threshold = <0x3b8260>;
			bif_threshold1 = <0x40d990>;
			bif_threshold2 = <0x419ce0>;
			bif_cv_under_threshold2 = <0x43e6d0>;
			pd_vbus_low_bound = <0x4c4b40>;
			pd_vbus_upper_bound = <0x895440>;
			pd_ichg_level_threshold = <0xf4240>;
			pd_stop_battery_soc = <0x50>;
			ibus_err = <0x0e>;
			vsys_watt = <0x4c4b40>;
			phandle = <0xfe>;
			fcp_charger_current = <0x2191c0>;
			fcp_charger_input_current = <0x155cc0>;
			bc12_charger = <0x16>;
			use_sw_chg_done;
			dpm_enable;
			sdp_battery_cv = <0x4398b0>;
			iterm = <0x30d40>;
			vbus_max_limit = <0x2cec>;
			dynamic_iterm_en;
			jeita_temp_t0_to_t1_iterm = <0x30d40>;
			jeita_temp_t1_to_t2_iterm = <0x30d40>;
			jeita_temp_t2_to_t3_iterm = <0x30d40>;
			jeita_temp_t3_to_t4_iterm = <0x30d40>;
			sdp_jeita_temp_t2_to_t3_cv = <0x4398b0>;
			sdp_jeita_temp_t2_to_t3_iterm = <0x30d40>;
			vdpm_buf_limit = <0x64>;
			vdpm_para = "-32767", "4000", "4300", "50", "4000", "4200", "4500", "50", "4200", "32767", "4600", "50";
			charge_full_design = <0x419ce0>;
		};

	direct_charger: direct_charger {
			need_wired_sw_off = <0x00>;
			compensate_r = <0x00>;
			dc_volt_ratio = <0x01>;
			use_5A = <0x00>;
			scp_cable_detect_enable = <0x00>;
			max_adaptor_vset = <0x157c>;
			max_tadapt = <0x73>;
			max_tls = <0x73>;
			ibat_abnormal_th = <0xc8>;
			first_cc_stage_timer_in_min = <0x00>;
			max_dc_bat_vol = <0x10fe>;
			min_dc_bat_vol = <0xdde>;
			charge_control_interval = <0x05>;
			threshold_caculation_interval = <0x05>;
			safety_monitor_interval = <0x05>;
			scp_work_on_charger = <0x00>;
			init_adapter_vset = <0x1130>;
			init_delt_vset = <0x12c>;
			vstep = <0x0a>;
			delta_err = <0xc8>;
			vol_err_th = <0x96>;
			full_path_res_max = <0x78>;
			standard_cable_full_path_res_max = <0xa0>;
			max_current_for_none_standard_cable = <0xbb8>;
			adaptor_leakage_current_th = <0x12c>;
			stage_need_to_jump = "-1";
			temp_para = "-32767", "10", "0", "10", "45", "4750", "45", "32767", "0";
			compatible = "direct_charger";
			status = "disabled";
			phandle = <0xcb>;
		};

	direct_charger_sc: direct_charger_sc {
			compatible = "direct_charger_sc";
			need_wired_sw_off = <0x00>;
			dc_volt_ratio = <0x02>;
			compensate_r = <0x00>;
			max_adaptor_vset = <0x2af8>;
			max_tadapt = <0x73>;
			max_tls = <0x73>;
			ibat_abnormal_th = <0xc8>;
			first_cc_stage_timer_in_min = <0x0e>;
			max_dc_bat_vol = <0x111c>;
			min_dc_bat_vol = <0xdde>;
			charge_control_interval = <0x05>;
			threshold_caculation_interval = <0x05>;
			safety_monitor_interval = <0x05>;
			scp_work_on_charger = <0x01>;
			init_adapter_vset = <0x2260>;
			init_delt_vset = <0x1c2>;
			vstep = <0x14>;
			delta_err = <0x12c>;
			vol_err_th = <0x12c>;
			full_path_res_max = <0x1f4>;
			standard_cable_full_path_res_max = <0x1f4>;
			max_current_for_none_standard_cable = <0x1770>;
			adaptor_leakage_current_th = <0x12c>;
			stage_need_to_jump = "-1";
			temp_para = "-32767", "10", "0", "10", "46", "12500", "46", "32767", "0";
			status = "ok";
			phandle = <0xcc>;
			use_5A = <0x01>;
			use_higher_vbat = <0x01>;
			adaptor_antifake_check_enable = <0x01>;
			adaptor_antifake_key_index = <0x02>;
			delta_err_10v2p25a = <0x96>;
			high_temp_hysteresis = <0x01>;
			gain_curr_10v2a = <0x12c>;
			gain_curr_10v2p25a = <0x1f4>;
			product_max_pwr = <0x101d0>;
			ui_max_pwr = <0x9c40>;
			volt_para = "4150", "8400", "6300", "4250", "6300", "5040", "4300", "5040", "4200", "4450", "4200", "2940", "4460", "2940", "1200";
			volt_para1 = "4200", "12200", "11000", "4250", "11000", "8400", "4300", "8400", "6300", "4380", "6300", "5040", "4450", "5040", "4200", "4460", "4200", "1200";
			bat_para = "ZGA", "10", "20", "volt_para", "ZGA", "20", "45", "volt_para1", "VDG", "10", "20", "volt_para", "VDG", "20", "45", "volt_para1", "default", "10", "20", "volt_para", "default", "20", "45", "volt_para1";
			second_resist_para = "0", "250", "0", "250", "450", "8000";
			vbat_error = "3", "120", "2", "-1", "3", "80", "1", "8000";
			current_ratio = "3", "6", "16", "2", "-1", "3", "9", "13", "1", "8000", "0", "9", "13", "0", "0";
			adapter_max_power_time_para = "3", "600", "6000", "4", "1200", "3000", "5", "600", "6000", "6", "600", "6000", "7", "600", "6000", "8", "600", "6000", "9", "1200", "3000", "10", "1200", "3000", "12", "600", "6000", "13", "600", "6000", "14", "600", "6000", "15", "1200", "3000";
			vstep_para = "2000", "80";
			cc_cable_detect_enable = <0x01>;
			cc_unsafe_sc_enable = <0x00>;
			is_show_ico_first = <0x01>;
			is_send_cable_type = <0x00>;
			support_multi_ic = <0x01>;
			vbat_comp_para = <0x0a 0x00 0x14 0x0a 0x01 0x14 0x12 0x00 0x07 0x12 0x01 0x07>;
			10v4a_cur_para = "-32767", "11000", "4000";
			rt_test_para = "1500", "105", "1500", "105", "1500", "105";
			resist_para = "0", "300", "6000", "300", "500", "5000";
			std_resist_para = "0", "300", "12500", "300", "500", "5000";
			10v2p25a_cur_para = "-32767", "5500", "2000", "5500", "9000", "2500", "9000", "10000", "2250", "10000", "10500", "2000", "10500", "32767", "1500";
		};

	honor_batt_identify: honor_batt_identify {
			compatible = "honor,battery-identify";
			status = "ok";
			phandle = <0xde>;
			pinctrl-names = "default";
			pinctrl-0 = <0x21c>;
			gpios = <0x02 0x13 0x00>;
			id_voltage_gpiov = <0x00 0x00>;
			id_sn_gpiov = <0x00 0x01>;
		};

	honor_batt_identifyxxxxx: honor_batt_identifyxxxx {
			compatible = "honor,battery-identifyxxx";
			status = "disabled";
			phandle = <0xdf>;
		};

	honor_batt_info: honor_batt_info {
			compatible = "honor,battery-information";
			sn-version = <0x01>;
			sn-check-type = <0x01>;
			shield_ct_sign = <0x01>;
			status = "ok";
			phandle = <0xdb>;
	
			battery_checker_0: battery_checker@0 {
				compatible = "honor,battery-authentication";
				matchable = <0x05>;
				id-in-grp = [01];
				chks-in-grp = [01];
				id-of-grp = [01];
				free-cycles = <0x0a>;
				sn-check-type = <0x00>;
				status = "ok";
				phandle = <0xdc>;
			};
	
			battery_checker_1: battery_checker@1 {
				compatible = "honor,battery-authentication";
				id-in-grp = [02];
				chks-in-grp = [02];
				id-of-grp = [01];
				free-cycles = <0x0a>;
				sn-check-type = <0x00>;
				status = "disabled";
				phandle = <0xdd>;
			};
		};

	honor_batt_soh: honor_batt_soh {
			compatible = "honor,battery-soh";
			basp = <0x01>;
			status = "ok";
			phandle = <0xc5>;
			ndc_vterm_step = <0x0a>;
		};

	honor_battery: honor_battery {
			compatible = "honor,battery";
			product_charger_support_powerpath;
			honor,icl_current = <0x7d0>;
			status = "okay";
			phandle = <0xbe>;
			voltage_max_design = <0x4398b0>;
			use_third_coul = <0x00>;
		};

	honor_battery_leakage: honor_battery_leakage {
			compatible = "honor,battery_leakage";
			max_temp = <0x1c2>;
			min_temp = <0x64>;
			max_20min_aveage_cur_ma = <0x0a>;
			max_1min_aveage_cur_ma = <0x64>;
			battery_psy_name = "battery";
			delta_item_threahold_ma = <0x32>;
			status = "disabled";
			phandle = <0xd9>;
		};

	honor_battery_temp: honor_battery_temp {
			compatible = "honor,battery_temp";
			status = "ok";
			phandle = <0x102>;
		};

	honor_bt_info: honor_bt_info {
			compatible = "honor,honor_bt_info";
			phandle = <0x19a>;
		};

	honor_charger: honor_charger {
			compatible = "honor,charger";
			status = "okay";
			phandle = <0xbb>;
			en_eoc_max_delay = <0x06>;
			powerdown_set_bl_delay_time_ms = "350";
			jeita_check_charge_enable;
		};

	honor_fuelguage {
			compatible = "honor,fuelguage";
			status = "okay";
		};

	honor_power_proxy: honor_power_proxy {
			compatible = "honor,power_proxy";
			battery_proxy = <0x01>;
			event_proxy = <0x01>;
			status = "disabled";
			phandle = <0xbf>;
		};

	honor_power_supply: honor_power_supply {
			compatible = "honor,power_supply";
			support_bat = <0x01>;
			support_raw_bat = <0x01>;
			support_assist_bat = <0x01>;
			bat_mode = <0x01>;
			status = "disabled";
			phandle = <0xc0>;
		};

	honor_ptst: honor_ptst {
			compatible = "honor,power_test";
			dc_mmi = <0x01>;
			dc_mmi_para = <0x2d 0x01 0x01 0x1388 0x05>;
			status = "ok";
			phandle = <0xc8>;
		};

	honor_sensor_info: honor,honor_sensor_info {
			phandle = <0x13f>;
			compatible = "honor,honor_sensor_info";
			bma4xy_direction = <0x03>;
			kx022_direction = <0x03>;
			lis2dwl_direction = <0x03>;
			honor_virt_prox = <0x00>;
			lsm6dsm_direction = <0x00>;
			bmi160_direction = <0x03>;
			icm4n607_direction = <0x00>;
			gyro_calibrate_timeout = <0x1388>;
			product_number = <0x16>;
			product_name = "gina";
			cali_check_type = <0x11>;
			aod_type = <0x01>;
			als_ud_algo = <0x01>;
			status = "okay";
		};

	honor_usb: honor_usb {
			maximum-speed = "unknown-speed";
			phandle = <0xc6>;
		};

	honor_wifi_info: honor_wifi_info {
			compatible = "honor,honor_wifi_info";
			phandle = <0x199>;
			status = "okay";
			ini_type = "GIA";
			wifi_chiptype = "WIFI_MTK_6635X";
			power_limit = "GIA";
			antenna_types = "GIA";
			wifi_cfg_type = "GIA_";
		};

	lk_charger: lk_charger {
			compatible = "mediatek,lk_charger";
			enable_anime;
			enable_pd20_reset;
			power_path_support;
			max_charger_voltage = <0xb71b00>;
			fast_charge_voltage = <0x2dc6c0>;
			usb_charger_current = <0x7a120>;
			ac_charger_current = <0x100590>;
			ac_charger_input_current = <0x100590>;
			non_std_ac_charger_current = <0x100590>;
			charging_host_charger_current = <0x16e360>;
			ta_ac_charger_current = <0x2dc6c0>;
			pd_charger_current = <0x7a120>;
			temp_t4_threshold = <0x32>;
			temp_t3_threshold = <0x2d>;
			temp_t1_threshold = <0x00>;
			phandle = <0xfd>;
			iprechg_current = <0x30d40>;
			is_power_path;
			poweron_charger_enable = <0x01>;
			led_brightness = <0xc8>;
		};

	mt6359_gauge {
			compatible = "mediatek,mt6359_gauge";
			gauge_name = "gauge";
			alias_name = "MT6359";
		};

	mt_charger: mt_charger {
			compatible = "mediatek,mt-charger";
			phandle = <0xfc>;
		};

	mtk_battery_temp: mtk_battery_temp {
			compatible = "honor,mtk_battery_temp";
			status = "ok";
			phandle = <0x101>;
			v_pullup = <0xaf0>;
			r_pullup = <0x55f0>;
			com_r_fg_value = <0x05>;
			no_bat_temp_compensate = <0x00>;
			com_fg_meter_resistance = <0x64>;
		};

	pd_adapter: pd_adapter {
			compatible = "mediatek,pd_adapter";
			adapter_name = "pd_adapter";
			phandle = <0xff>;
		};

	pd_dpm: pd_dpm {
			compatible = "honor,pd_dpm";
			tcp_name = "type_c_port0";
			support_dp = <0x00>;
			switch_manual_enable = <0x00>;
			abnormal_cc_detection = <0x01>;
			status = "ok";
			phandle = <0xce>;
		};

	power_thermalzone: power_thermalzone {
			compatible = "honor,power_thermalzone";
			status = "ok";
			phandle = <0x100>;
	
			sensors {
	
				sensor0 {
					sensor_name = "usb_port";
					ops_name = "uscp";
					adc_channel = <0x00>;
					ntc_index = <0x02>;
				};
	
				sensor1 {
					sensor_name = "mtk_batt_temp";
					ops_name = "mtk_batt_temp";
					adc_channel = <0x02>;
					ntc_index = <0x07>;
				};
			};
		};

	rt-pd-manager {
			compatible = "mediatek,rt-pd-manager";
		};

	scpsys: power-controller@10006000 {
			compatible = "mediatek,mt6877-scpsys", "syscon";
			reg = <0x00 0x10006000 0x00 0x1000 0x00 0x10001000 0x00 0x1000 0x00 0x1020e000 0x00 0x1000 0x00 0x10215000 0x00 0x1000>;
			#clock-cells = <0x01>;
			phandle = <0x41>;
		};

	typec_mux_switch: typec_mux_switch {
			compatible = "mediatek,typec_mux_switch";
			status = "okay";
			phandle = <0x1ce>;
		};

	upower: upower {
			compatible = "mediatek,mt6833-upower";
			phandle = <0x148>;
		};

	usb_short_circuit_protect: usb_short_circuit_protect {
			compatible = "honor,usb_short_circuit_protect";
			dmd_hiz_enable = <0x01>;
			uscp_threshold_tusb = <0x28>;
			open_mosfet_temp = <0x13>;
			close_mosfet_temp = <0x08>;
			open_hiz_temp = <0x0d>;
			interval_switch_temp = <0x07>;
			io-channels = <0x52 0x05>;
			io-channel-names = "uscp_channel";
			gpio_uscp = <0x02 0x6f 0x00>;
			status = "ok";
			phandle = <0x104>;
		};

	vbus_channel_boost_gpio: vbus_channel_boost_gpio {
			compatible = "honor,vbus_channel_boost_gpio";
			status = "disabled";
			phandle = <0xbc>;
		};

	vbus_channel_charger: vbus_channel_charger {
			compatible = "honor,vbus_channel_charger";
			status = "disabled";
			phandle = <0xbd>;
		};

	wireless_charger: wireless_charger {
			compatible = "honor,wireless_charger";
			standard_tx_adaptor = <0x05>;
			antifake_key_index = <0x01>;
			bst5v_ignore_vbus_only = <0x00>;
			hvc_need_5vbst = <0x00>;
			ui_max_pwr = <0x6978>;
			rx_vout_err_ratio = <0x51>;
			rx_iout_min = <0x96>;
			rx_iout_step = <0x64>;
			rx_iout_ctrl_para = <0x00 0x64 0xc8 0x64 0xc8 0x12c 0xc8 0x12c 0x190 0x12c 0x190 0x1f4 0x190 0x1f4 0x258 0x1f4 0x258 0x2bc 0x258 0x2bc 0x320 0x2bc 0x320 0x384 0x320 0x270f 0x44c>;
			product_para = <0x3a98 0x4650 0x640>;
			tx_prop = "0x01", "SDP", "0", "0", "5000", "475", "0x02", "CDP", "0", "0", "5000", "1000", "0x03", "NON_STD", "0", "0", "5000", "1000", "0x04", "DCP", "0", "0", "5000", "1000", "0x05", "FCP", "0", "1", "9000", "2000", "0x06", "SCP", "0", "1", "5000", "1000", "0x07", "PD", "0", "1", "5000", "1000", "0x08", "QC", "0", "1", "5000", "1000", "0x09", "OTG_A", "0", "0", "5000", "475", "0x0A", "OTG_B", "0", "0", "5000", "475", "0xff", "ERR", "0", "0", "5000", "1000";
			volt_mode = <0x00 0x1388 0x01 0x2328 0x02 0x2ee0 0x03 0x3a98>;
			status = "disabled";
			phandle = <0xd5>;
		};

